VERSION ""

NS_ :

BS_:

BU_: IOT_Gateway BMC

BO_ 3221225472 VECTOR__INDEPENDENT_SIG_MSG: 0 Vector__XXX
 SG_ RUL_HP_1 : 0|16@1+ (1,0) [0|65535] "" Vector__XXX
 SG_ RUL_HP_0 : 0|16@1+ (1,0) [0|65535] "" Vector__XXX
 SG_ RUL_HE_1 : 0|16@1+ (1,0) [0|65535] "" Vector__XXX
 SG_ RUL_HE_0 : 0|16@1+ (1,0) [0|65535] "" Vector__XXX

BO_ 130 CellPwrHi_4: 64 BMC
 SG_ TAuxBattMonEgyHi_16_1 : 496|16@1+ (0.0078125,0) [0|511.9921875] "°K"  IOT_Gateway
 SG_ TAuxBattMonEgyHi_15_1 : 480|16@1+ (0.0078125,0) [0|511.9921875] "°K"  IOT_Gateway
 SG_ TAuxBattMonEgyHi_14_1 : 464|16@1+ (0.0078125,0) [0|511.9921875] "°K"  IOT_Gateway
 SG_ TAuxBattMonEgyHi_13_1 : 448|16@1+ (0.0078125,0) [0|511.9921875] "°K"  IOT_Gateway
 SG_ TAuxBattMonEgyHi_12_1 : 432|16@1+ (0.0078125,0) [0|511.9921875] "°K"  IOT_Gateway
 SG_ TAuxBattMonEgyHi_11_1 : 416|16@1+ (0.0078125,0) [0|511.9921875] "°K"  IOT_Gateway
 SG_ TAuxBattMonEgyHi_10_1 : 400|16@1+ (0.0078125,0) [0|511.9921875] "°K"  IOT_Gateway
 SG_ TAuxBattMonEgyHi_9_1 : 384|16@1+ (0.0078125,0) [0|511.9921875] "°K"  IOT_Gateway
 SG_ TAuxBattMonEgyHi_8_1 : 368|16@1+ (0.0078125,0) [0|511.9921875] "°K"  IOT_Gateway
 SG_ TAuxBattMonEgyHi_7_1 : 352|16@1+ (0.0078125,0) [0|511.9921875] "°K"  IOT_Gateway
 SG_ TAuxBattMonEgyHi_6_1 : 336|16@1+ (0.0078125,0) [0|511.9921875] "°K"  IOT_Gateway
 SG_ TAuxBattMonEgyHi_5_1 : 320|16@1+ (0.0078125,0) [0|511.9921875] "°K"  IOT_Gateway
 SG_ TAuxBattMonEgyHi_4_1 : 304|16@1+ (0.0078125,0) [0|511.9921875] "°K"  IOT_Gateway
 SG_ TAuxBattMonEgyHi_3_1 : 288|16@1+ (0.0078125,0) [0|511.9921875] "°K"  IOT_Gateway
 SG_ TAuxBattMonEgyHi_2_1 : 272|16@1+ (0.0078125,0) [0|511.9921875] "°K"  IOT_Gateway
 SG_ TAuxBattMonEgyHi_1_1 : 256|16@1+ (0.0078125,0) [0|511.9921875] "°K"  IOT_Gateway
 SG_ TAuxBattMonPwrHi_16_1 : 240|16@1+ (0.0078125,0) [0|511.9921875] "°K"  IOT_Gateway
 SG_ TAuxBattMonPwrHi_15_1 : 224|16@1+ (0.0078125,0) [0|511.9921875] "°K"  IOT_Gateway
 SG_ TAuxBattMonPwrHi_14_1 : 208|16@1+ (0.0078125,0) [0|511.9921875] "°K"  IOT_Gateway
 SG_ TAuxBattMonPwrHi_13_1 : 192|16@1+ (0.0078125,0) [0|511.9921875] "°K"  IOT_Gateway
 SG_ TAuxBattMonPwrHi_12_1 : 176|16@1+ (0.0078125,0) [0|511.9921875] "°K"  IOT_Gateway
 SG_ TAuxBattMonPwrHi_11_1 : 160|16@1+ (0.0078125,0) [0|511.9921875] "°K"  IOT_Gateway
 SG_ TAuxBattMonPwrHi_10_1 : 144|16@1+ (0.0078125,0) [0|511.9921875] "°K"  IOT_Gateway
 SG_ TAuxBattMonPwrHi_9_1 : 128|16@1+ (0.0078125,0) [0|511.9921875] "°K"  IOT_Gateway
 SG_ TAuxBattMonPwrHi_8_1 : 112|16@1+ (0.0078125,0) [0|511.9921875] "°K"  IOT_Gateway
 SG_ TAuxBattMonPwrHi_7_1 : 96|16@1+ (0.0078125,0) [0|511.9921875] "°K"  IOT_Gateway
 SG_ TAuxBattMonPwrHi_6_1 : 80|16@1+ (0.0078125,0) [0|511.9921875] "°K"  IOT_Gateway
 SG_ TAuxBattMonPwrHi_5_1 : 64|16@1+ (0.0078125,0) [0|511.9921875] "°K"  IOT_Gateway
 SG_ TAuxBattMonPwrHi_4_1 : 48|16@1+ (0.0078125,0) [0|511.9921875] "°K"  IOT_Gateway
 SG_ TAuxBattMonPwrHi_3_1 : 32|16@1+ (0.0078125,0) [0|511.9921875] "°K"  IOT_Gateway
 SG_ TAuxBattMonPwrHi_2_1 : 16|16@1+ (0.0078125,0) [0|511.9921875] "°K"  IOT_Gateway
 SG_ TAuxBattMonPwrHi_1_1 : 0|16@1+ (0.0078125,0) [0|511.9921875] "°K"  IOT_Gateway

BO_ 111 TCellBattEgyHi_16: 12 BMC
 SG_ TCellBattEgyHi_16_6 : 80|16@1+ (0.0078125,0) [0|511.9921875] "°K"  IOT_Gateway
 SG_ TCellBattEgyHi_16_5 : 64|16@1+ (0.0078125,0) [0|511.9921875] "°K"  IOT_Gateway
 SG_ TCellBattEgyHi_16_4 : 48|16@1+ (0.0078125,0) [0|511.9921875] "°K"  IOT_Gateway
 SG_ TCellBattEgyHi_16_3 : 32|16@1+ (0.0078125,0) [0|511.9921875] "°K"  IOT_Gateway
 SG_ TCellBattEgyHi_16_2 : 16|16@1+ (0.0078125,0) [0|511.9921875] "°K"  IOT_Gateway
 SG_ TCellBattEgyHi_16_1 : 0|16@1+ (0.0078125,0) [0|511.9921875] "°K"  IOT_Gateway

BO_ 110 TCellBattEgyHi_15: 12 BMC
 SG_ TCellBattEgyHi_15_6 : 80|16@1+ (0.0078125,0) [0|511.9921875] "°K"  IOT_Gateway
 SG_ TCellBattEgyHi_15_5 : 64|16@1+ (0.0078125,0) [0|511.9921875] "°K"  IOT_Gateway
 SG_ TCellBattEgyHi_15_4 : 48|16@1+ (0.0078125,0) [0|511.9921875] "°K"  IOT_Gateway
 SG_ TCellBattEgyHi_15_3 : 32|16@1+ (0.0078125,0) [0|511.9921875] "°K"  IOT_Gateway
 SG_ TCellBattEgyHi_15_2 : 16|16@1+ (0.0078125,0) [0|511.9921875] "°K"  IOT_Gateway
 SG_ TCellBattEgyHi_15_1 : 0|16@1+ (0.0078125,0) [0|511.9921875] "°K"  IOT_Gateway

BO_ 109 TCellBattEgyHi_14: 12 BMC
 SG_ TCellBattEgyHi_14_6 : 80|16@1+ (0.0078125,0) [0|511.9921875] "°K"  IOT_Gateway
 SG_ TCellBattEgyHi_14_5 : 64|16@1+ (0.0078125,0) [0|511.9921875] "°K"  IOT_Gateway
 SG_ TCellBattEgyHi_14_4 : 48|16@1+ (0.0078125,0) [0|511.9921875] "°K"  IOT_Gateway
 SG_ TCellBattEgyHi_14_3 : 32|16@1+ (0.0078125,0) [0|511.9921875] "°K"  IOT_Gateway
 SG_ TCellBattEgyHi_14_2 : 16|16@1+ (0.0078125,0) [0|511.9921875] "°K"  IOT_Gateway
 SG_ TCellBattEgyHi_14_1 : 0|16@1+ (0.0078125,0) [0|511.9921875] "°K"  IOT_Gateway

BO_ 108 TCellBattEgyHi_13: 12 BMC
 SG_ TCellBattEgyHi_13_6 : 80|16@1+ (0.0078125,0) [0|511.9921875] "°K"  IOT_Gateway
 SG_ TCellBattEgyHi_13_5 : 64|16@1+ (0.0078125,0) [0|511.9921875] "°K"  IOT_Gateway
 SG_ TCellBattEgyHi_13_4 : 48|16@1+ (0.0078125,0) [0|511.9921875] "°K"  IOT_Gateway
 SG_ TCellBattEgyHi_13_3 : 32|16@1+ (0.0078125,0) [0|511.9921875] "°K"  IOT_Gateway
 SG_ TCellBattEgyHi_13_2 : 16|16@1+ (0.0078125,0) [0|511.9921875] "°K"  IOT_Gateway
 SG_ TCellBattEgyHi_13_1 : 0|16@1+ (0.0078125,0) [0|511.9921875] "°K"  IOT_Gateway

BO_ 95 TCellBattPwrHi_16: 12 BMC
 SG_ TCellBattPwrHi_16_6 : 80|16@1+ (0.0078125,0) [0|511.9921875] "°K" Vector__XXX
 SG_ TCellBattPwrHi_16_5 : 64|16@1+ (0.0078125,0) [0|511.9921875] "°K" Vector__XXX
 SG_ TCellBattPwrHi_16_4 : 48|16@1+ (0.0078125,0) [0|511.9921875] "°K" Vector__XXX
 SG_ TCellBattPwrHi_16_3 : 32|16@1+ (0.0078125,0) [0|511.9921875] "°K" Vector__XXX
 SG_ TCellBattPwrHi_16_2 : 16|16@1+ (0.0078125,0) [0|511.9921875] "°K" Vector__XXX
 SG_ TCellBattPwrHi_16_1 : 0|16@1+ (0.0078125,0) [0|511.9921875] "°K" Vector__XXX

BO_ 94 TCellBattPwrHi_15: 12 BMC
 SG_ TCellBattPwrHi_15_6 : 80|16@1+ (0.0078125,0) [0|511.9921875] "°K" Vector__XXX
 SG_ TCellBattPwrHi_15_5 : 64|16@1+ (0.0078125,0) [0|511.9921875] "°K" Vector__XXX
 SG_ TCellBattPwrHi_15_4 : 48|16@1+ (0.0078125,0) [0|511.9921875] "°K" Vector__XXX
 SG_ TCellBattPwrHi_15_3 : 32|16@1+ (0.0078125,0) [0|511.9921875] "°K" Vector__XXX
 SG_ TCellBattPwrHi_15_2 : 16|16@1+ (0.0078125,0) [0|511.9921875] "°K" Vector__XXX
 SG_ TCellBattPwrHi_15_1 : 0|16@1+ (0.0078125,0) [0|511.9921875] "°K" Vector__XXX

BO_ 93 TCellBattPwrHi_14: 12 BMC
 SG_ TCellBattPwrHi_14_6 : 80|16@1+ (0.0078125,0) [0|511.9921875] "°K" Vector__XXX
 SG_ TCellBattPwrHi_14_5 : 64|16@1+ (0.0078125,0) [0|511.9921875] "°K" Vector__XXX
 SG_ TCellBattPwrHi_14_4 : 48|16@1+ (0.0078125,0) [0|511.9921875] "°K" Vector__XXX
 SG_ TCellBattPwrHi_14_3 : 32|16@1+ (0.0078125,0) [0|511.9921875] "°K" Vector__XXX
 SG_ TCellBattPwrHi_14_2 : 16|16@1+ (0.0078125,0) [0|511.9921875] "°K" Vector__XXX
 SG_ TCellBattPwrHi_14_1 : 0|16@1+ (0.0078125,0) [0|511.9921875] "°K" Vector__XXX

BO_ 92 TCellBattPwrHi_13: 12 BMC
 SG_ TCellBattPwrHi_13_6 : 80|16@1+ (0.0078125,0) [0|511.9921875] "°K" Vector__XXX
 SG_ TCellBattPwrHi_13_5 : 64|16@1+ (0.0078125,0) [0|511.9921875] "°K" Vector__XXX
 SG_ TCellBattPwrHi_13_4 : 48|16@1+ (0.0078125,0) [0|511.9921875] "°K" Vector__XXX
 SG_ TCellBattPwrHi_13_3 : 32|16@1+ (0.0078125,0) [0|511.9921875] "°K" Vector__XXX
 SG_ TCellBattPwrHi_13_2 : 16|16@1+ (0.0078125,0) [0|511.9921875] "°K" Vector__XXX
 SG_ TCellBattPwrHi_13_1 : 0|16@1+ (0.0078125,0) [0|511.9921875] "°K" Vector__XXX

BO_ 1654 Sensor_Msg8_8: 8 BMC
 SG_ VERSION_MINOR_8 : 8|8@1+ (1,0) [0|255] ""  IOT_Gateway
 SG_ VERSION_MAJOR_8 : 0|8@1+ (1,0) [0|255] ""  IOT_Gateway

BO_ 1638 Sensor_Msg8_7: 8 BMC
 SG_ VERSION_MINOR_7 : 8|8@1+ (1,0) [0|255] ""  IOT_Gateway
 SG_ VERSION_MAJOR_7 : 0|8@1+ (1,0) [0|255] ""  IOT_Gateway

BO_ 1606 Sensor_Msg8_5: 8 BMC
 SG_ VERSION_MINOR_5 : 8|8@1+ (1,0) [0|255] ""  IOT_Gateway
 SG_ VERSION_MAJOR_5 : 0|8@1+ (1,0) [0|255] ""  IOT_Gateway

BO_ 1590 Sensor_Msg8_4: 8 BMC
 SG_ VERSION_MINOR_4 : 8|8@1+ (1,0) [0|255] ""  IOT_Gateway
 SG_ VERSION_MAJOR_4 : 0|8@1+ (1,0) [0|255] ""  IOT_Gateway

BO_ 1622 Sensor_Msg8_6: 8 BMC
 SG_ VERSION_MINOR_6 : 8|8@1+ (1,0) [0|255] ""  IOT_Gateway
 SG_ VERSION_MAJOR_6 : 0|8@1+ (1,0) [0|255] ""  IOT_Gateway

BO_ 1574 Sensor_Msg8_3: 8 BMC
 SG_ VERSION_MINOR_3 : 8|8@1+ (1,0) [0|255] ""  IOT_Gateway
 SG_ VERSION_MAJOR_3 : 0|8@1+ (1,0) [0|255] ""  IOT_Gateway

BO_ 1558 Sensor_Msg8_2: 8 BMC
 SG_ VERSION_MINOR_2 : 8|8@1+ (1,0) [0|255] ""  IOT_Gateway
 SG_ VERSION_MAJOR_2 : 0|8@1+ (1,0) [0|255] ""  IOT_Gateway

BO_ 1542 Sensor_Msg8_1: 8 BMC
 SG_ VERSION_MINOR_1 : 8|8@1+ (1,0) [0|255] ""  IOT_Gateway
 SG_ VERSION_MAJOR_1 : 0|8@1+ (1,0) [0|255] ""  IOT_Gateway

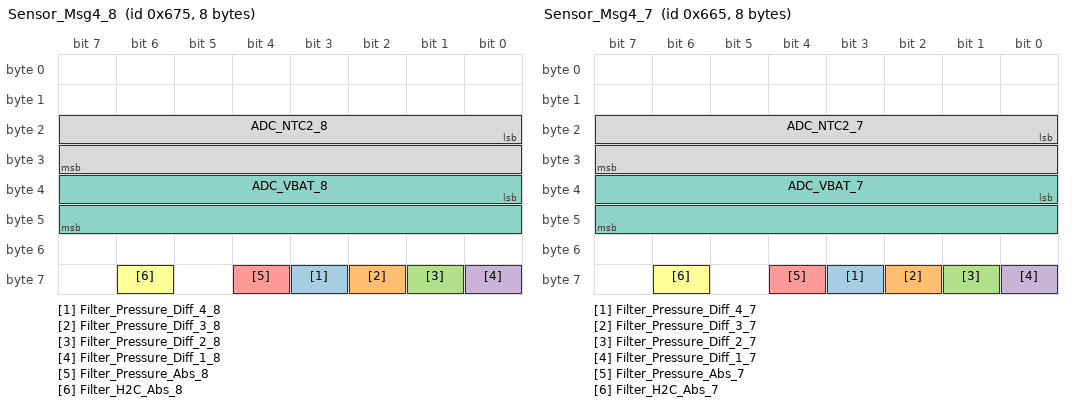
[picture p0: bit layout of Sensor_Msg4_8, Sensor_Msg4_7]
BO_ 1653 Sensor_Msg4_8: 8 BMC
 SG_ Filter_Pressure_Diff_4_8 : 59|1@1+ (1,0) [0|1] ""  IOT_Gateway
 SG_ Filter_Pressure_Diff_3_8 : 58|1@1+ (1,0) [0|1] ""  IOT_Gateway
 SG_ Filter_Pressure_Diff_2_8 : 57|1@1+ (1,0) [0|1] ""  IOT_Gateway
 SG_ Filter_Pressure_Diff_1_8 : 56|1@1+ (1,0) [0|1] ""  IOT_Gateway
 SG_ Filter_Pressure_Abs_8 : 60|1@1+ (1,0) [0|1] ""  IOT_Gateway
 SG_ Filter_H2C_Abs_8 : 62|1@1+ (1,0) [0|1] ""  IOT_Gateway
 SG_ ADC_VBAT_8 : 32|16@1- (0.01,0) [0|100] "V"  IOT_Gateway
 SG_ ADC_NTC2_8 : 16|16@1- (0.01,0) [-40|125] "°C"  IOT_Gateway

BO_ 1637 Sensor_Msg4_7: 8 BMC
 SG_ Filter_Pressure_Diff_4_7 : 59|1@1+ (1,0) [0|1] ""  IOT_Gateway
 SG_ Filter_Pressure_Diff_3_7 : 58|1@1+ (1,0) [0|1] ""  IOT_Gateway
 SG_ Filter_Pressure_Diff_2_7 : 57|1@1+ (1,0) [0|1] ""  IOT_Gateway
 SG_ Filter_Pressure_Diff_1_7 : 56|1@1+ (1,0) [0|1] ""  IOT_Gateway
 SG_ Filter_Pressure_Abs_7 : 60|1@1+ (1,0) [0|1] ""  IOT_Gateway
 SG_ Filter_H2C_Abs_7 : 62|1@1+ (1,0) [0|1] ""  IOT_Gateway
 SG_ ADC_VBAT_7 : 32|16@1- (0.01,0) [0|100] "V"  IOT_Gateway
 SG_ ADC_NTC2_7 : 16|16@1- (0.01,0) [-40|125] "°C"  IOT_Gateway

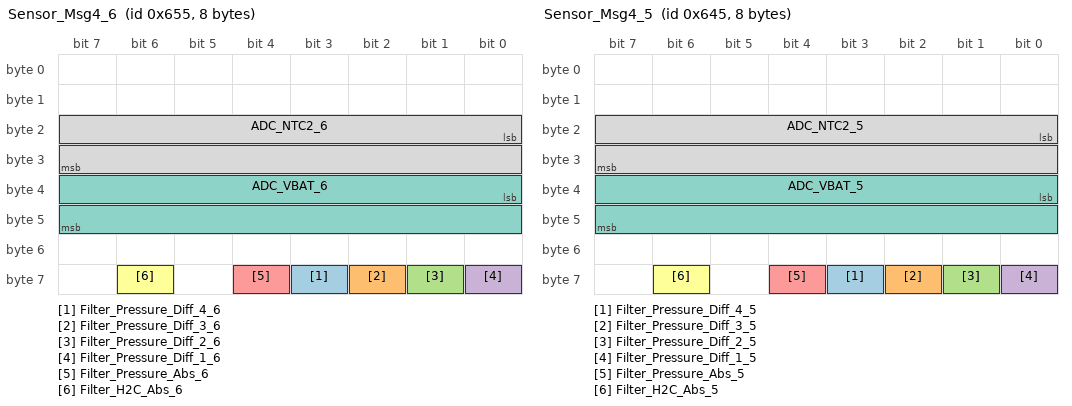
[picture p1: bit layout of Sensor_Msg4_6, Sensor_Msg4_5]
BO_ 1621 Sensor_Msg4_6: 8 BMC
 SG_ Filter_Pressure_Diff_4_6 : 59|1@1+ (1,0) [0|1] ""  IOT_Gateway
 SG_ Filter_Pressure_Diff_3_6 : 58|1@1+ (1,0) [0|1] ""  IOT_Gateway
 SG_ Filter_Pressure_Diff_2_6 : 57|1@1+ (1,0) [0|1] ""  IOT_Gateway
 SG_ Filter_Pressure_Diff_1_6 : 56|1@1+ (1,0) [0|1] ""  IOT_Gateway
 SG_ Filter_Pressure_Abs_6 : 60|1@1+ (1,0) [0|1] ""  IOT_Gateway
 SG_ Filter_H2C_Abs_6 : 62|1@1+ (1,0) [0|1] ""  IOT_Gateway
 SG_ ADC_VBAT_6 : 32|16@1- (0.01,0) [0|100] "V"  IOT_Gateway
 SG_ ADC_NTC2_6 : 16|16@1- (0.01,0) [-40|125] "°C"  IOT_Gateway

BO_ 1605 Sensor_Msg4_5: 8 BMC
 SG_ Filter_Pressure_Diff_4_5 : 59|1@1+ (1,0) [0|1] ""  IOT_Gateway
 SG_ Filter_Pressure_Diff_3_5 : 58|1@1+ (1,0) [0|1] ""  IOT_Gateway
 SG_ Filter_Pressure_Diff_2_5 : 57|1@1+ (1,0) [0|1] ""  IOT_Gateway
 SG_ Filter_Pressure_Diff_1_5 : 56|1@1+ (1,0) [0|1] ""  IOT_Gateway
 SG_ Filter_Pressure_Abs_5 : 60|1@1+ (1,0) [0|1] ""  IOT_Gateway
 SG_ Filter_H2C_Abs_5 : 62|1@1+ (1,0) [0|1] ""  IOT_Gateway
 SG_ ADC_VBAT_5 : 32|16@1- (0.01,0) [0|100] "V"  IOT_Gateway
 SG_ ADC_NTC2_5 : 16|16@1- (0.01,0) [-40|125] "°C"  IOT_Gateway

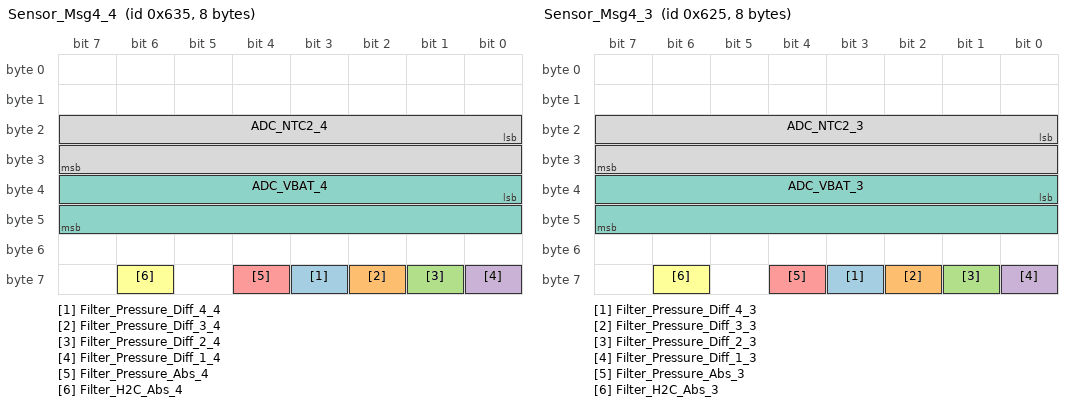
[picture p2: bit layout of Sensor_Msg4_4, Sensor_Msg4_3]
BO_ 1589 Sensor_Msg4_4: 8 BMC
 SG_ Filter_Pressure_Diff_4_4 : 59|1@1+ (1,0) [0|1] ""  IOT_Gateway
 SG_ Filter_Pressure_Diff_3_4 : 58|1@1+ (1,0) [0|1] ""  IOT_Gateway
 SG_ Filter_Pressure_Diff_2_4 : 57|1@1+ (1,0) [0|1] ""  IOT_Gateway
 SG_ Filter_Pressure_Diff_1_4 : 56|1@1+ (1,0) [0|1] ""  IOT_Gateway
 SG_ Filter_Pressure_Abs_4 : 60|1@1+ (1,0) [0|1] ""  IOT_Gateway
 SG_ Filter_H2C_Abs_4 : 62|1@1+ (1,0) [0|1] ""  IOT_Gateway
 SG_ ADC_VBAT_4 : 32|16@1- (0.01,0) [0|100] "V"  IOT_Gateway
 SG_ ADC_NTC2_4 : 16|16@1- (0.01,0) [-40|125] "°C"  IOT_Gateway

BO_ 1573 Sensor_Msg4_3: 8 BMC
 SG_ Filter_Pressure_Diff_4_3 : 59|1@1+ (1,0) [0|1] ""  IOT_Gateway
 SG_ Filter_Pressure_Diff_3_3 : 58|1@1+ (1,0) [0|1] ""  IOT_Gateway
 SG_ Filter_Pressure_Diff_2_3 : 57|1@1+ (1,0) [0|1] ""  IOT_Gateway
 SG_ Filter_Pressure_Diff_1_3 : 56|1@1+ (1,0) [0|1] ""  IOT_Gateway
 SG_ Filter_Pressure_Abs_3 : 60|1@1+ (1,0) [0|1] ""  IOT_Gateway
 SG_ Filter_H2C_Abs_3 : 62|1@1+ (1,0) [0|1] ""  IOT_Gateway
 SG_ ADC_VBAT_3 : 32|16@1- (0.01,0) [0|100] "V"  IOT_Gateway
 SG_ ADC_NTC2_3 : 16|16@1- (0.01,0) [-40|125] "°C"  IOT_Gateway

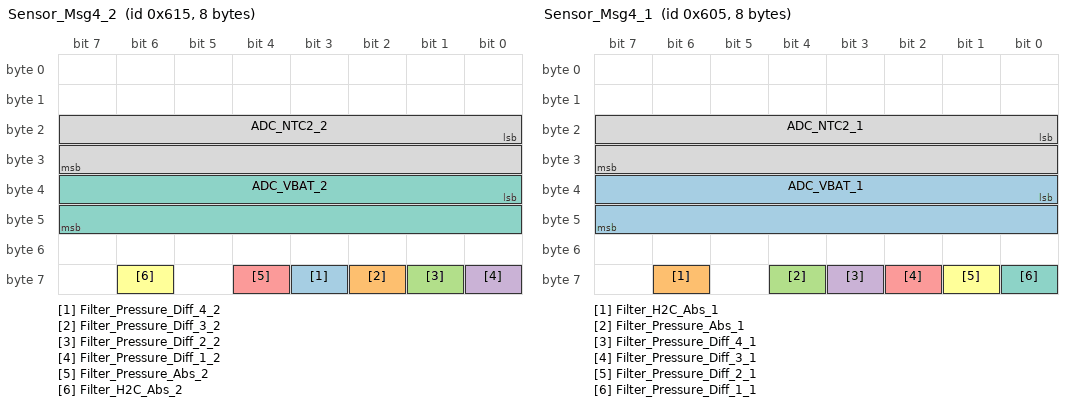
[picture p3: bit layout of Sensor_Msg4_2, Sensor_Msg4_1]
BO_ 1557 Sensor_Msg4_2: 8 BMC
 SG_ Filter_Pressure_Diff_4_2 : 59|1@1+ (1,0) [0|1] ""  IOT_Gateway
 SG_ Filter_Pressure_Diff_3_2 : 58|1@1+ (1,0) [0|1] ""  IOT_Gateway
 SG_ Filter_Pressure_Diff_2_2 : 57|1@1+ (1,0) [0|1] ""  IOT_Gateway
 SG_ Filter_Pressure_Diff_1_2 : 56|1@1+ (1,0) [0|1] ""  IOT_Gateway
 SG_ Filter_Pressure_Abs_2 : 60|1@1+ (1,0) [0|1] ""  IOT_Gateway
 SG_ Filter_H2C_Abs_2 : 62|1@1+ (1,0) [0|1] ""  IOT_Gateway
 SG_ ADC_VBAT_2 : 32|16@1- (0.01,0) [0|100] "V"  IOT_Gateway
 SG_ ADC_NTC2_2 : 16|16@1- (0.01,0) [-40|125] "°C"  IOT_Gateway

BO_ 1541 Sensor_Msg4_1: 8 BMC
 SG_ ADC_VBAT_1 : 32|16@1- (0.01,0) [0|100] "V"  IOT_Gateway
 SG_ Filter_H2C_Abs_1 : 62|1@1+ (1,0) [0|1] ""  IOT_Gateway
 SG_ Filter_Pressure_Abs_1 : 60|1@1+ (1,0) [0|1] ""  IOT_Gateway
 SG_ Filter_Pressure_Diff_4_1 : 59|1@1+ (1,0) [0|1] ""  IOT_Gateway
 SG_ Filter_Pressure_Diff_3_1 : 58|1@1+ (1,0) [0|1] ""  IOT_Gateway
 SG_ Filter_Pressure_Diff_2_1 : 57|1@1+ (1,0) [0|1] ""  IOT_Gateway
 SG_ Filter_Pressure_Diff_1_1 : 56|1@1+ (1,0) [0|1] ""  IOT_Gateway
 SG_ ADC_NTC2_1 : 16|16@1- (0.01,0) [-40|125] "°C"  IOT_Gateway

BO_ 1652 Sensor_Msg3_8: 8 BMC
 SG_ KP466_Status_8 : 16|8@1+ (1,0) [0|255] ""  IOT_Gateway
 SG_ KP466_Pressure_8 : 32|32@1- (0.001,0) [60|165] "kPa"  IOT_Gateway

BO_ 1636 Sensor_Msg3_7: 8 BMC
 SG_ KP466_Status_7 : 16|8@1+ (1,0) [0|255] ""  IOT_Gateway
 SG_ KP466_Pressure_7 : 32|32@1- (0.001,0) [60|165] "kPa"  IOT_Gateway

BO_ 1620 Sensor_Msg3_6: 8 BMC
 SG_ KP466_Status_6 : 16|8@1+ (1,0) [0|255] ""  IOT_Gateway
 SG_ KP466_Pressure_6 : 32|32@1- (0.001,0) [60|165] "kPa"  IOT_Gateway

BO_ 1604 Sensor_Msg3_5: 8 BMC
 SG_ KP466_Status_5 : 16|8@1+ (1,0) [0|255] ""  IOT_Gateway
 SG_ KP466_Pressure_5 : 32|32@1- (0.001,0) [60|165] "kPa"  IOT_Gateway

BO_ 1588 Sensor_Msg3_4: 8 BMC
 SG_ KP466_Status_4 : 16|8@1+ (1,0) [0|255] ""  IOT_Gateway
 SG_ KP466_Pressure_4 : 32|32@1- (0.001,0) [60|165] "kPa"  IOT_Gateway

BO_ 1572 Sensor_Msg3_3: 8 BMC
 SG_ KP466_Status_3 : 16|8@1+ (1,0) [0|255] ""  IOT_Gateway
 SG_ KP466_Pressure_3 : 32|32@1- (0.001,0) [60|165] "kPa"  IOT_Gateway

BO_ 1556 Sensor_Msg3_2: 8 BMC
 SG_ KP466_Status_2 : 16|8@1+ (1,0) [0|255] ""  IOT_Gateway
 SG_ KP466_Pressure_2 : 32|32@1- (0.001,0) [60|165] "kPa"  IOT_Gateway

BO_ 1540 Sensor_Msg3_1: 8 BMC
 SG_ KP466_Pressure_1 : 32|32@1- (0.001,0) [60|165] "kPa"  IOT_Gateway
 SG_ KP466_Status_1 : 16|8@1+ (1,0) [0|255] ""  IOT_Gateway

BO_ 1650 Sensor_Msg1_8: 8 BMC
 SG_ SHT_Status_8 : 56|8@1+ (1,0) [0|255] ""  IOT_Gateway
 SG_ SHT_Humidity_8 : 0|32@1- (0.001,0) [0|100] "%"  IOT_Gateway

BO_ 1634 Sensor_Msg1_7: 8 BMC
 SG_ SHT_Status_7 : 56|8@1+ (1,0) [0|255] ""  IOT_Gateway
 SG_ SHT_Humidity_7 : 0|32@1- (0.001,0) [0|100] "%"  IOT_Gateway

BO_ 1618 Sensor_Msg1_6: 8 BMC
 SG_ SHT_Status_6 : 56|8@1+ (1,0) [0|255] ""  IOT_Gateway
 SG_ SHT_Humidity_6 : 0|32@1- (0.001,0) [0|100] "%"  IOT_Gateway

BO_ 1602 Sensor_Msg1_5: 8 BMC
 SG_ SHT_Status_5 : 56|8@1+ (1,0) [0|255] ""  IOT_Gateway
 SG_ SHT_Humidity_5 : 0|32@1- (0.001,0) [0|100] "%"  IOT_Gateway

BO_ 1586 Sensor_Msg1_4: 8 BMC
 SG_ SHT_Status_4 : 56|8@1+ (1,0) [0|255] ""  IOT_Gateway
 SG_ SHT_Humidity_4 : 0|32@1- (0.001,0) [0|100] "%"  IOT_Gateway

BO_ 1570 Sensor_Msg1_3: 8 BMC
 SG_ SHT_Status_3 : 56|8@1+ (1,0) [0|255] ""  IOT_Gateway
 SG_ SHT_Humidity_3 : 0|32@1- (0.001,0) [0|100] "%"  IOT_Gateway

BO_ 1554 Sensor_Msg1_2: 8 BMC
 SG_ SHT_Status_2 : 56|8@1+ (1,0) [0|255] ""  IOT_Gateway
 SG_ SHT_Humidity_2 : 0|32@1- (0.001,0) [0|100] "%"  IOT_Gateway

BO_ 1538 Sensor_Msg1_1: 8 BMC
 SG_ SHT_Status_1 : 56|8@1+ (1,0) [0|255] ""  IOT_Gateway
 SG_ SHT_Humidity_1 : 0|32@1- (0.001,0) [0|100] "%"  IOT_Gateway

BO_ 1649 Sensor_Msg0_8: 8 BMC
 SG_ SHT_Temperature_8 : 32|32@1- (0.001,0) [-40|105] "°C"  IOT_Gateway

BO_ 1633 Sensor_Msg0_7: 8 BMC
 SG_ SHT_Temperature_7 : 32|32@1- (0.001,0) [-40|105] "°C"  IOT_Gateway

BO_ 1617 Sensor_Msg0_6: 8 BMC
 SG_ SHT_Temperature_6 : 32|32@1- (0.001,0) [-40|105] "°C"  IOT_Gateway

BO_ 1601 Sensor_Msg0_5: 8 BMC
 SG_ SHT_Temperature_5 : 32|32@1- (0.001,0) [-40|105] "°C"  IOT_Gateway

BO_ 1585 Sensor_Msg0_4: 8 BMC
 SG_ SHT_Temperature_4 : 32|32@1- (0.001,0) [-40|105] "°C"  IOT_Gateway

BO_ 1569 Sensor_Msg0_3: 8 BMC
 SG_ SHT_Temperature_3 : 32|32@1- (0.001,0) [-40|105] "°C"  IOT_Gateway

BO_ 1553 Sensor_Msg0_2: 8 BMC
 SG_ SHT_Temperature_2 : 32|32@1- (0.001,0) [-40|105] "°C"  IOT_Gateway

BO_ 1537 Sensor_Msg0_1: 8 BMC
 SG_ SHT_Temperature_1 : 32|32@1- (0.001,0) [-40|105] "°C"  IOT_Gateway

BO_ 1648 H2CS_DF_8: 8 BMC
 SG_ H2CS_H2C_8 : 16|12@1+ (0.01,-2) [-2|38.95] "%"  IOT_Gateway

BO_ 1632 H2CS_DF_7: 8 BMC
 SG_ H2CS_H2C_7 : 16|12@1+ (0.01,-2) [-2|38.95] "%"  IOT_Gateway

BO_ 1616 H2CS_DF_6: 8 BMC
 SG_ H2CS_H2C_6 : 16|12@1+ (0.01,-2) [-2|38.95] "%"  IOT_Gateway

BO_ 1600 H2CS_DF_5: 8 BMC
 SG_ H2CS_H2C_5 : 16|12@1+ (0.01,-2) [-2|38.95] "%"  IOT_Gateway

BO_ 1584 H2CS_DF_4: 8 BMC
 SG_ H2CS_H2C_4 : 16|12@1+ (0.01,-2) [-2|38.95] "%"  IOT_Gateway

BO_ 1568 H2CS_DF_3: 8 BMC
 SG_ H2CS_H2C_3 : 16|12@1+ (0.01,-2) [-2|38.95] "%"  IOT_Gateway

BO_ 1552 H2CS_DF_2: 8 BMC
 SG_ H2CS_H2C_2 : 16|12@1+ (0.01,-2) [-2|38.95] "%"  IOT_Gateway

BO_ 1536 H2CS_DF_1: 8 BMC
 SG_ H2CS_H2C_1 : 16|12@1+ (0.01,-2) [-2|38.95] "%"  IOT_Gateway

BO_ 127 RatChaCellBattEgyHi_8: 64 BMC
 SG_ RatChaCellBattEgyHi_16_16 : 496|16@1+ (0.006103515625,-2) [-2|1.9999] ""  IOT_Gateway
 SG_ RatChaCellBattEgyHi_16_15 : 480|16@1+ (0.006103515625,-2) [-2|1.9999] ""  IOT_Gateway
 SG_ RatChaCellBattEgyHi_16_14 : 464|16@1+ (0.006103515625,-2) [-2|1.9999] ""  IOT_Gateway
 SG_ RatChaCellBattEgyHi_16_13 : 448|16@1+ (0.006103515625,-2) [-2|1.9999] ""  IOT_Gateway
 SG_ RatChaCellBattEgyHi_16_12 : 432|16@1+ (0.006103515625,-2) [-2|1.9999] ""  IOT_Gateway
 SG_ RatChaCellBattEgyHi_16_11 : 416|16@1+ (0.006103515625,-2) [-2|1.9999] ""  IOT_Gateway
 SG_ RatChaCellBattEgyHi_16_10 : 400|16@1+ (0.006103515625,-2) [-2|1.9999] ""  IOT_Gateway
 SG_ RatChaCellBattEgyHi_16_9 : 384|16@1+ (0.006103515625,-2) [-2|1.9999] ""  IOT_Gateway
 SG_ RatChaCellBattEgyHi_16_8 : 368|16@1+ (0.006103515625,-2) [-2|1.9999] ""  IOT_Gateway
 SG_ RatChaCellBattEgyHi_16_7 : 352|16@1+ (0.006103515625,-2) [-2|1.9999] ""  IOT_Gateway
 SG_ RatChaCellBattEgyHi_16_6 : 336|16@1+ (0.006103515625,-2) [-2|1.9999] ""  IOT_Gateway
 SG_ RatChaCellBattEgyHi_16_5 : 320|16@1+ (0.006103515625,-2) [-2|1.9999] ""  IOT_Gateway
 SG_ RatChaCellBattEgyHi_16_4 : 304|16@1+ (0.006103515625,-2) [-2|1.9999] ""  IOT_Gateway
 SG_ RatChaCellBattEgyHi_16_3 : 288|16@1+ (0.006103515625,-2) [-2|1.9999] ""  IOT_Gateway
 SG_ RatChaCellBattEgyHi_16_2 : 272|16@1+ (0.006103515625,-2) [-2|1.9999] ""  IOT_Gateway
 SG_ RatChaCellBattEgyHi_16_1 : 256|16@1+ (0.006103515625,-2) [-2|1.9999] ""  IOT_Gateway
 SG_ RatChaCellBattEgyHi_15_16 : 240|16@1+ (0.006103515625,-2) [-2|1.9999] ""  IOT_Gateway
 SG_ RatChaCellBattEgyHi_15_15 : 224|16@1+ (0.006103515625,-2) [-2|1.9999] ""  IOT_Gateway
 SG_ RatChaCellBattEgyHi_15_14 : 208|16@1+ (0.006103515625,-2) [-2|1.9999] ""  IOT_Gateway
 SG_ RatChaCellBattEgyHi_15_13 : 192|16@1+ (0.006103515625,-2) [-2|1.9999] ""  IOT_Gateway
 SG_ RatChaCellBattEgyHi_15_12 : 176|16@1+ (0.006103515625,-2) [-2|1.9999] ""  IOT_Gateway
 SG_ RatChaCellBattEgyHi_15_11 : 160|16@1+ (0.006103515625,-2) [-2|1.9999] ""  IOT_Gateway
 SG_ RatChaCellBattEgyHi_15_10 : 144|16@1+ (0.006103515625,-2) [-2|1.9999] ""  IOT_Gateway
 SG_ RatChaCellBattEgyHi_15_9 : 128|16@1+ (0.006103515625,-2) [-2|1.9999] ""  IOT_Gateway
 SG_ RatChaCellBattEgyHi_15_8 : 112|16@1+ (0.006103515625,-2) [-2|1.9999] ""  IOT_Gateway
 SG_ RatChaCellBattEgyHi_15_7 : 96|16@1+ (0.006103515625,-2) [-2|1.9999] ""  IOT_Gateway
 SG_ RatChaCellBattEgyHi_15_6 : 80|16@1+ (0.006103515625,-2) [-2|1.9999] ""  IOT_Gateway
 SG_ RatChaCellBattEgyHi_15_5 : 64|16@1+ (0.006103515625,-2) [-2|1.9999] ""  IOT_Gateway
 SG_ RatChaCellBattEgyHi_15_4 : 48|16@1+ (0.006103515625,-2) [-2|1.9999] ""  IOT_Gateway
 SG_ RatChaCellBattEgyHi_15_3 : 32|16@1+ (0.006103515625,-2) [-2|1.9999] ""  IOT_Gateway
 SG_ RatChaCellBattEgyHi_15_2 : 16|16@1+ (0.006103515625,-2) [-2|1.9999] ""  IOT_Gateway
 SG_ RatChaCellBattEgyHi_15_1 : 0|16@1+ (0.006103515625,-2) [-2|1.9999] ""  IOT_Gateway

BO_ 126 RatChaCellBattEgyHi_7: 64 BMC
 SG_ RatChaCellBattEgyHi_14_16 : 496|16@1+ (0.006103515625,-2) [-2|1.9999] ""  IOT_Gateway
 SG_ RatChaCellBattEgyHi_14_15 : 480|16@1+ (0.006103515625,-2) [-2|1.9999] ""  IOT_Gateway
 SG_ RatChaCellBattEgyHi_14_14 : 464|16@1+ (0.006103515625,-2) [-2|1.9999] ""  IOT_Gateway
 SG_ RatChaCellBattEgyHi_14_13 : 448|16@1+ (0.006103515625,-2) [-2|1.9999] ""  IOT_Gateway
 SG_ RatChaCellBattEgyHi_14_12 : 432|16@1+ (0.006103515625,-2) [-2|1.9999] ""  IOT_Gateway
 SG_ RatChaCellBattEgyHi_14_11 : 416|16@1+ (0.006103515625,-2) [-2|1.9999] ""  IOT_Gateway
 SG_ RatChaCellBattEgyHi_14_10 : 400|16@1+ (0.006103515625,-2) [-2|1.9999] ""  IOT_Gateway
 SG_ RatChaCellBattEgyHi_14_9 : 384|16@1+ (0.006103515625,-2) [-2|1.9999] ""  IOT_Gateway
 SG_ RatChaCellBattEgyHi_14_8 : 368|16@1+ (0.006103515625,-2) [-2|1.9999] ""  IOT_Gateway
 SG_ RatChaCellBattEgyHi_14_7 : 352|16@1+ (0.006103515625,-2) [-2|1.9999] ""  IOT_Gateway
 SG_ RatChaCellBattEgyHi_14_6 : 336|16@1+ (0.006103515625,-2) [-2|1.9999] ""  IOT_Gateway
 SG_ RatChaCellBattEgyHi_14_5 : 320|16@1+ (0.006103515625,-2) [-2|1.9999] ""  IOT_Gateway
 SG_ RatChaCellBattEgyHi_14_4 : 304|16@1+ (0.006103515625,-2) [-2|1.9999] ""  IOT_Gateway
 SG_ RatChaCellBattEgyHi_14_3 : 288|16@1+ (0.006103515625,-2) [-2|1.9999] ""  IOT_Gateway
 SG_ RatChaCellBattEgyHi_14_2 : 272|16@1+ (0.006103515625,-2) [-2|1.9999] ""  IOT_Gateway
 SG_ RatChaCellBattEgyHi_14_1 : 256|16@1+ (0.006103515625,-2) [-2|1.9999] ""  IOT_Gateway
 SG_ RatChaCellBattEgyHi_13_16 : 240|16@1+ (0.006103515625,-2) [-2|1.9999] ""  IOT_Gateway
 SG_ RatChaCellBattEgyHi_13_15 : 224|16@1+ (0.006103515625,-2) [-2|1.9999] ""  IOT_Gateway
 SG_ RatChaCellBattEgyHi_13_14 : 208|16@1+ (0.006103515625,-2) [-2|1.9999] ""  IOT_Gateway
 SG_ RatChaCellBattEgyHi_13_13 : 192|16@1+ (0.006103515625,-2) [-2|1.9999] ""  IOT_Gateway
 SG_ RatChaCellBattEgyHi_13_12 : 176|16@1+ (0.006103515625,-2) [-2|1.9999] ""  IOT_Gateway
 SG_ RatChaCellBattEgyHi_13_11 : 160|16@1+ (0.006103515625,-2) [-2|1.9999] ""  IOT_Gateway
 SG_ RatChaCellBattEgyHi_13_10 : 144|16@1+ (0.006103515625,-2) [-2|1.9999] ""  IOT_Gateway
 SG_ RatChaCellBattEgyHi_13_9 : 128|16@1+ (0.006103515625,-2) [-2|1.9999] ""  IOT_Gateway
 SG_ RatChaCellBattEgyHi_13_8 : 112|16@1+ (0.006103515625,-2) [-2|1.9999] ""  IOT_Gateway
 SG_ RatChaCellBattEgyHi_13_7 : 96|16@1+ (0.006103515625,-2) [-2|1.9999] ""  IOT_Gateway
 SG_ RatChaCellBattEgyHi_13_6 : 80|16@1+ (0.006103515625,-2) [-2|1.9999] ""  IOT_Gateway
 SG_ RatChaCellBattEgyHi_13_5 : 64|16@1+ (0.006103515625,-2) [-2|1.9999] ""  IOT_Gateway
 SG_ RatChaCellBattEgyHi_13_4 : 48|16@1+ (0.006103515625,-2) [-2|1.9999] ""  IOT_Gateway
 SG_ RatChaCellBattEgyHi_13_3 : 32|16@1+ (0.006103515625,-2) [-2|1.9999] ""  IOT_Gateway
 SG_ RatChaCellBattEgyHi_13_2 : 16|16@1+ (0.006103515625,-2) [-2|1.9999] ""  IOT_Gateway
 SG_ RatChaCellBattEgyHi_13_1 : 0|16@1+ (0.006103515625,-2) [-2|1.9999] ""  IOT_Gateway

BO_ 125 RatChaCellBattEgyHi_6: 64 BMC
 SG_ RatChaCellBattEgyHi_12_16 : 496|16@1+ (0.006103515625,-2) [-2|1.9999] ""  IOT_Gateway
 SG_ RatChaCellBattEgyHi_12_15 : 480|16@1+ (0.006103515625,-2) [-2|1.9999] ""  IOT_Gateway
 SG_ RatChaCellBattEgyHi_12_14 : 464|16@1+ (0.006103515625,-2) [-2|1.9999] ""  IOT_Gateway
 SG_ RatChaCellBattEgyHi_12_13 : 448|16@1+ (0.006103515625,-2) [-2|1.9999] ""  IOT_Gateway
 SG_ RatChaCellBattEgyHi_12_12 : 432|16@1+ (0.006103515625,-2) [-2|1.9999] ""  IOT_Gateway
 SG_ RatChaCellBattEgyHi_12_11 : 416|16@1+ (0.006103515625,-2) [-2|1.9999] ""  IOT_Gateway
 SG_ RatChaCellBattEgyHi_12_10 : 400|16@1+ (0.006103515625,-2) [-2|1.9999] ""  IOT_Gateway
 SG_ RatChaCellBattEgyHi_12_9 : 384|16@1+ (0.006103515625,-2) [-2|1.9999] ""  IOT_Gateway
 SG_ RatChaCellBattEgyHi_12_8 : 368|16@1+ (0.006103515625,-2) [-2|1.9999] ""  IOT_Gateway
 SG_ RatChaCellBattEgyHi_12_7 : 352|16@1+ (0.006103515625,-2) [-2|1.9999] ""  IOT_Gateway
 SG_ RatChaCellBattEgyHi_12_6 : 336|16@1+ (0.006103515625,-2) [-2|1.9999] ""  IOT_Gateway
 SG_ RatChaCellBattEgyHi_12_5 : 320|16@1+ (0.006103515625,-2) [-2|1.9999] ""  IOT_Gateway
 SG_ RatChaCellBattEgyHi_12_4 : 304|16@1+ (0.006103515625,-2) [-2|1.9999] ""  IOT_Gateway
 SG_ RatChaCellBattEgyHi_12_3 : 288|16@1+ (0.006103515625,-2) [-2|1.9999] ""  IOT_Gateway
 SG_ RatChaCellBattEgyHi_12_2 : 272|16@1+ (0.006103515625,-2) [-2|1.9999] ""  IOT_Gateway
 SG_ RatChaCellBattEgyHi_12_1 : 256|16@1+ (0.006103515625,-2) [-2|1.9999] ""  IOT_Gateway
 SG_ RatChaCellBattEgyHi_11_16 : 240|16@1+ (0.006103515625,-2) [-2|1.9999] ""  IOT_Gateway
 SG_ RatChaCellBattEgyHi_11_15 : 224|16@1+ (0.006103515625,-2) [-2|1.9999] ""  IOT_Gateway
 SG_ RatChaCellBattEgyHi_11_14 : 208|16@1+ (0.006103515625,-2) [-2|1.9999] ""  IOT_Gateway
 SG_ RatChaCellBattEgyHi_11_13 : 192|16@1+ (0.006103515625,-2) [-2|1.9999] ""  IOT_Gateway
 SG_ RatChaCellBattEgyHi_11_12 : 176|16@1+ (0.006103515625,-2) [-2|1.9999] ""  IOT_Gateway
 SG_ RatChaCellBattEgyHi_11_11 : 160|16@1+ (0.006103515625,-2) [-2|1.9999] ""  IOT_Gateway
 SG_ RatChaCellBattEgyHi_11_10 : 144|16@1+ (0.006103515625,-2) [-2|1.9999] ""  IOT_Gateway
 SG_ RatChaCellBattEgyHi_11_9 : 128|16@1+ (0.006103515625,-2) [-2|1.9999] ""  IOT_Gateway
 SG_ RatChaCellBattEgyHi_11_8 : 112|16@1+ (0.006103515625,-2) [-2|1.9999] ""  IOT_Gateway
 SG_ RatChaCellBattEgyHi_11_7 : 96|16@1+ (0.006103515625,-2) [-2|1.9999] ""  IOT_Gateway
 SG_ RatChaCellBattEgyHi_11_6 : 80|16@1+ (0.006103515625,-2) [-2|1.9999] ""  IOT_Gateway
 SG_ RatChaCellBattEgyHi_11_5 : 64|16@1+ (0.006103515625,-2) [-2|1.9999] ""  IOT_Gateway
 SG_ RatChaCellBattEgyHi_11_4 : 48|16@1+ (0.006103515625,-2) [-2|1.9999] ""  IOT_Gateway
 SG_ RatChaCellBattEgyHi_11_3 : 32|16@1+ (0.006103515625,-2) [-2|1.9999] ""  IOT_Gateway
 SG_ RatChaCellBattEgyHi_11_2 : 16|16@1+ (0.006103515625,-2) [-2|1.9999] ""  IOT_Gateway
 SG_ RatChaCellBattEgyHi_11_1 : 0|16@1+ (0.006103515625,-2) [-2|1.9999] ""  IOT_Gateway

BO_ 124 RatChaCellBattEgyHi_5: 64 BMC
 SG_ RatChaCellBattEgyHi_10_16 : 496|16@1+ (0.006103515625,-2) [-2|1.9999] ""  IOT_Gateway
 SG_ RatChaCellBattEgyHi_10_15 : 480|16@1+ (0.006103515625,-2) [-2|1.9999] ""  IOT_Gateway
 SG_ RatChaCellBattEgyHi_10_14 : 464|16@1+ (0.006103515625,-2) [-2|1.9999] ""  IOT_Gateway
 SG_ RatChaCellBattEgyHi_10_13 : 448|16@1+ (0.006103515625,-2) [-2|1.9999] ""  IOT_Gateway
 SG_ RatChaCellBattEgyHi_10_12 : 432|16@1+ (0.006103515625,-2) [-2|1.9999] ""  IOT_Gateway
 SG_ RatChaCellBattEgyHi_10_11 : 416|16@1+ (0.006103515625,-2) [-2|1.9999] ""  IOT_Gateway
 SG_ RatChaCellBattEgyHi_10_10 : 400|16@1+ (0.006103515625,-2) [-2|1.9999] ""  IOT_Gateway
 SG_ RatChaCellBattEgyHi_10_9 : 384|16@1+ (0.006103515625,-2) [-2|1.9999] ""  IOT_Gateway
 SG_ RatChaCellBattEgyHi_10_8 : 368|16@1+ (0.006103515625,-2) [-2|1.9999] ""  IOT_Gateway
 SG_ RatChaCellBattEgyHi_10_7 : 352|16@1+ (0.006103515625,-2) [-2|1.9999] ""  IOT_Gateway
 SG_ RatChaCellBattEgyHi_10_6 : 336|16@1+ (0.006103515625,-2) [-2|1.9999] ""  IOT_Gateway
 SG_ RatChaCellBattEgyHi_10_5 : 320|16@1+ (0.006103515625,-2) [-2|1.9999] ""  IOT_Gateway
 SG_ RatChaCellBattEgyHi_10_4 : 304|16@1+ (0.006103515625,-2) [-2|1.9999] ""  IOT_Gateway
 SG_ RatChaCellBattEgyHi_10_3 : 288|16@1+ (0.006103515625,-2) [-2|1.9999] ""  IOT_Gateway
 SG_ RatChaCellBattEgyHi_10_2 : 272|16@1+ (0.006103515625,-2) [-2|1.9999] ""  IOT_Gateway
 SG_ RatChaCellBattEgyHi_10_1 : 256|16@1+ (0.006103515625,-2) [-2|1.9999] ""  IOT_Gateway
 SG_ RatChaCellBattEgyHi_9_16 : 240|16@1+ (0.006103515625,-2) [-2|1.9999] ""  IOT_Gateway
 SG_ RatChaCellBattEgyHi_9_15 : 224|16@1+ (0.006103515625,-2) [-2|1.9999] ""  IOT_Gateway
 SG_ RatChaCellBattEgyHi_9_14 : 208|16@1+ (0.006103515625,-2) [-2|1.9999] ""  IOT_Gateway
 SG_ RatChaCellBattEgyHi_9_13 : 192|16@1+ (0.006103515625,-2) [-2|1.9999] ""  IOT_Gateway
 SG_ RatChaCellBattEgyHi_9_12 : 176|16@1+ (0.006103515625,-2) [-2|1.9999] ""  IOT_Gateway
 SG_ RatChaCellBattEgyHi_9_11 : 160|16@1+ (0.006103515625,-2) [-2|1.9999] ""  IOT_Gateway
 SG_ RatChaCellBattEgyHi_9_10 : 144|16@1+ (0.006103515625,-2) [-2|1.9999] ""  IOT_Gateway
 SG_ RatChaCellBattEgyHi_9_9 : 128|16@1+ (0.006103515625,-2) [-2|1.9999] ""  IOT_Gateway
 SG_ RatChaCellBattEgyHi_9_8 : 112|16@1+ (0.006103515625,-2) [-2|1.9999] ""  IOT_Gateway
 SG_ RatChaCellBattEgyHi_9_7 : 96|16@1+ (0.006103515625,-2) [-2|1.9999] ""  IOT_Gateway
 SG_ RatChaCellBattEgyHi_9_6 : 80|16@1+ (0.006103515625,-2) [-2|1.9999] ""  IOT_Gateway
 SG_ RatChaCellBattEgyHi_9_5 : 64|16@1+ (0.006103515625,-2) [-2|1.9999] ""  IOT_Gateway
 SG_ RatChaCellBattEgyHi_9_4 : 48|16@1+ (0.006103515625,-2) [-2|1.9999] ""  IOT_Gateway
 SG_ RatChaCellBattEgyHi_9_3 : 32|16@1+ (0.006103515625,-2) [-2|1.9999] ""  IOT_Gateway
 SG_ RatChaCellBattEgyHi_9_2 : 16|16@1+ (0.006103515625,-2) [-2|1.9999] ""  IOT_Gateway
 SG_ RatChaCellBattEgyHi_9_1 : 0|16@1+ (0.006103515625,-2) [-2|1.9999] ""  IOT_Gateway

BO_ 123 RatChaCellBattEgyHi_4: 64 BMC
 SG_ RatChaCellBattEgyHi_8_16 : 496|16@1+ (0.006103515625,-2) [-2|1.9999] ""  IOT_Gateway
 SG_ RatChaCellBattEgyHi_8_15 : 480|16@1+ (0.006103515625,-2) [-2|1.9999] ""  IOT_Gateway
 SG_ RatChaCellBattEgyHi_8_14 : 464|16@1+ (0.006103515625,-2) [-2|1.9999] ""  IOT_Gateway
 SG_ RatChaCellBattEgyHi_8_13 : 448|16@1+ (0.006103515625,-2) [-2|1.9999] ""  IOT_Gateway
 SG_ RatChaCellBattEgyHi_8_12 : 432|16@1+ (0.006103515625,-2) [-2|1.9999] ""  IOT_Gateway
 SG_ RatChaCellBattEgyHi_8_11 : 416|16@1+ (0.006103515625,-2) [-2|1.9999] ""  IOT_Gateway
 SG_ RatChaCellBattEgyHi_8_10 : 400|16@1+ (0.006103515625,-2) [-2|1.9999] ""  IOT_Gateway
 SG_ RatChaCellBattEgyHi_8_9 : 384|16@1+ (0.006103515625,-2) [-2|1.9999] ""  IOT_Gateway
 SG_ RatChaCellBattEgyHi_8_8 : 368|16@1+ (0.006103515625,-2) [-2|1.9999] ""  IOT_Gateway
 SG_ RatChaCellBattEgyHi_8_7 : 352|16@1+ (0.006103515625,-2) [-2|1.9999] ""  IOT_Gateway
 SG_ RatChaCellBattEgyHi_8_6 : 336|16@1+ (0.006103515625,-2) [-2|1.9999] ""  IOT_Gateway
 SG_ RatChaCellBattEgyHi_8_5 : 320|16@1+ (0.006103515625,-2) [-2|1.9999] ""  IOT_Gateway
 SG_ RatChaCellBattEgyHi_8_4 : 304|16@1+ (0.006103515625,-2) [-2|1.9999] ""  IOT_Gateway
 SG_ RatChaCellBattEgyHi_8_3 : 288|16@1+ (0.006103515625,-2) [-2|1.9999] ""  IOT_Gateway
 SG_ RatChaCellBattEgyHi_8_2 : 272|16@1+ (0.006103515625,-2) [-2|1.9999] ""  IOT_Gateway
 SG_ RatChaCellBattEgyHi_8_1 : 256|16@1+ (0.006103515625,-2) [-2|1.9999] ""  IOT_Gateway
 SG_ RatChaCellBattEgyHi_7_16 : 240|16@1+ (0.006103515625,-2) [-2|1.9999] ""  IOT_Gateway
 SG_ RatChaCellBattEgyHi_7_15 : 224|16@1+ (0.006103515625,-2) [-2|1.9999] ""  IOT_Gateway
 SG_ RatChaCellBattEgyHi_7_14 : 208|16@1+ (0.006103515625,-2) [-2|1.9999] ""  IOT_Gateway
 SG_ RatChaCellBattEgyHi_7_13 : 192|16@1+ (0.006103515625,-2) [-2|1.9999] ""  IOT_Gateway
 SG_ RatChaCellBattEgyHi_7_12 : 176|16@1+ (0.006103515625,-2) [-2|1.9999] ""  IOT_Gateway
 SG_ RatChaCellBattEgyHi_7_11 : 160|16@1+ (0.006103515625,-2) [-2|1.9999] ""  IOT_Gateway
 SG_ RatChaCellBattEgyHi_7_10 : 144|16@1+ (0.006103515625,-2) [-2|1.9999] ""  IOT_Gateway
 SG_ RatChaCellBattEgyHi_7_9 : 128|16@1+ (0.006103515625,-2) [-2|1.9999] ""  IOT_Gateway
 SG_ RatChaCellBattEgyHi_7_8 : 112|16@1+ (0.006103515625,-2) [-2|1.9999] ""  IOT_Gateway
 SG_ RatChaCellBattEgyHi_7_7 : 96|16@1+ (0.006103515625,-2) [-2|1.9999] ""  IOT_Gateway
 SG_ RatChaCellBattEgyHi_7_6 : 80|16@1+ (0.006103515625,-2) [-2|1.9999] ""  IOT_Gateway
 SG_ RatChaCellBattEgyHi_7_5 : 64|16@1+ (0.006103515625,-2) [-2|1.9999] ""  IOT_Gateway
 SG_ RatChaCellBattEgyHi_7_4 : 48|16@1+ (0.006103515625,-2) [-2|1.9999] ""  IOT_Gateway
 SG_ RatChaCellBattEgyHi_7_3 : 32|16@1+ (0.006103515625,-2) [-2|1.9999] ""  IOT_Gateway
 SG_ RatChaCellBattEgyHi_7_2 : 16|16@1+ (0.006103515625,-2) [-2|1.9999] ""  IOT_Gateway
 SG_ RatChaCellBattEgyHi_7_1 : 0|16@1+ (0.006103515625,-2) [-2|1.9999] ""  IOT_Gateway

BO_ 122 RatChaCellBattEgyHi_3: 64 BMC
 SG_ RatChaCellBattEgyHi_6_16 : 496|16@1+ (0.006103515625,-2) [-2|1.9999] ""  IOT_Gateway
 SG_ RatChaCellBattEgyHi_6_15 : 480|16@1+ (0.006103515625,-2) [-2|1.9999] ""  IOT_Gateway
 SG_ RatChaCellBattEgyHi_6_14 : 464|16@1+ (0.006103515625,-2) [-2|1.9999] ""  IOT_Gateway
 SG_ RatChaCellBattEgyHi_6_13 : 448|16@1+ (0.006103515625,-2) [-2|1.9999] ""  IOT_Gateway
 SG_ RatChaCellBattEgyHi_6_12 : 432|16@1+ (0.006103515625,-2) [-2|1.9999] ""  IOT_Gateway
 SG_ RatChaCellBattEgyHi_6_11 : 416|16@1+ (0.006103515625,-2) [-2|1.9999] ""  IOT_Gateway
 SG_ RatChaCellBattEgyHi_6_10 : 400|16@1+ (0.006103515625,-2) [-2|1.9999] ""  IOT_Gateway
 SG_ RatChaCellBattEgyHi_6_9 : 384|16@1+ (0.006103515625,-2) [-2|1.9999] ""  IOT_Gateway
 SG_ RatChaCellBattEgyHi_6_8 : 368|16@1+ (0.006103515625,-2) [-2|1.9999] ""  IOT_Gateway
 SG_ RatChaCellBattEgyHi_6_7 : 352|16@1+ (0.006103515625,-2) [-2|1.9999] ""  IOT_Gateway
 SG_ RatChaCellBattEgyHi_6_6 : 336|16@1+ (0.006103515625,-2) [-2|1.9999] ""  IOT_Gateway
 SG_ RatChaCellBattEgyHi_6_5 : 320|16@1+ (0.006103515625,-2) [-2|1.9999] ""  IOT_Gateway
 SG_ RatChaCellBattEgyHi_6_4 : 304|16@1+ (0.006103515625,-2) [-2|1.9999] ""  IOT_Gateway
 SG_ RatChaCellBattEgyHi_6_3 : 288|16@1+ (0.006103515625,-2) [-2|1.9999] ""  IOT_Gateway
 SG_ RatChaCellBattEgyHi_6_2 : 272|16@1+ (0.006103515625,-2) [-2|1.9999] ""  IOT_Gateway
 SG_ RatChaCellBattEgyHi_6_1 : 256|16@1+ (0.006103515625,-2) [-2|1.9999] ""  IOT_Gateway
 SG_ RatChaCellBattEgyHi_5_16 : 240|16@1+ (0.006103515625,-2) [-2|1.9999] ""  IOT_Gateway
 SG_ RatChaCellBattEgyHi_5_15 : 224|16@1+ (0.006103515625,-2) [-2|1.9999] ""  IOT_Gateway
 SG_ RatChaCellBattEgyHi_5_14 : 208|16@1+ (0.006103515625,-2) [-2|1.9999] ""  IOT_Gateway
 SG_ RatChaCellBattEgyHi_5_13 : 192|16@1+ (0.006103515625,-2) [-2|1.9999] ""  IOT_Gateway
 SG_ RatChaCellBattEgyHi_5_12 : 176|16@1+ (0.006103515625,-2) [-2|1.9999] ""  IOT_Gateway
 SG_ RatChaCellBattEgyHi_5_11 : 160|16@1+ (0.006103515625,-2) [-2|1.9999] ""  IOT_Gateway
 SG_ RatChaCellBattEgyHi_5_10 : 144|16@1+ (0.006103515625,-2) [-2|1.9999] ""  IOT_Gateway
 SG_ RatChaCellBattEgyHi_5_9 : 128|16@1+ (0.006103515625,-2) [-2|1.9999] ""  IOT_Gateway
 SG_ RatChaCellBattEgyHi_5_8 : 112|16@1+ (0.006103515625,-2) [-2|1.9999] ""  IOT_Gateway
 SG_ RatChaCellBattEgyHi_5_7 : 96|16@1+ (0.006103515625,-2) [-2|1.9999] ""  IOT_Gateway
 SG_ RatChaCellBattEgyHi_5_6 : 80|16@1+ (0.006103515625,-2) [-2|1.9999] ""  IOT_Gateway
 SG_ RatChaCellBattEgyHi_5_5 : 64|16@1+ (0.006103515625,-2) [-2|1.9999] ""  IOT_Gateway
 SG_ RatChaCellBattEgyHi_5_4 : 48|16@1+ (0.006103515625,-2) [-2|1.9999] ""  IOT_Gateway
 SG_ RatChaCellBattEgyHi_5_3 : 32|16@1+ (0.006103515625,-2) [-2|1.9999] ""  IOT_Gateway
 SG_ RatChaCellBattEgyHi_5_2 : 16|16@1+ (0.006103515625,-2) [-2|1.9999] ""  IOT_Gateway
 SG_ RatChaCellBattEgyHi_5_1 : 0|16@1+ (0.006103515625,-2) [-2|1.9999] ""  IOT_Gateway

BO_ 121 RatChaCellBattEgyHi_2: 64 BMC
 SG_ RatChaCellBattEgyHi_4_16 : 496|16@1+ (0.006103515625,-2) [-2|1.9999] ""  IOT_Gateway
 SG_ RatChaCellBattEgyHi_4_15 : 480|16@1+ (0.006103515625,-2) [-2|1.9999] ""  IOT_Gateway
 SG_ RatChaCellBattEgyHi_4_14 : 464|16@1+ (0.006103515625,-2) [-2|1.9999] ""  IOT_Gateway
 SG_ RatChaCellBattEgyHi_4_13 : 448|16@1+ (0.006103515625,-2) [-2|1.9999] ""  IOT_Gateway
 SG_ RatChaCellBattEgyHi_4_12 : 432|16@1+ (0.006103515625,-2) [-2|1.9999] ""  IOT_Gateway
 SG_ RatChaCellBattEgyHi_4_11 : 416|16@1+ (0.006103515625,-2) [-2|1.9999] ""  IOT_Gateway
 SG_ RatChaCellBattEgyHi_4_10 : 400|16@1+ (0.006103515625,-2) [-2|1.9999] ""  IOT_Gateway
 SG_ RatChaCellBattEgyHi_4_9 : 384|16@1+ (0.006103515625,-2) [-2|1.9999] ""  IOT_Gateway
 SG_ RatChaCellBattEgyHi_4_8 : 368|16@1+ (0.006103515625,-2) [-2|1.9999] ""  IOT_Gateway
 SG_ RatChaCellBattEgyHi_4_7 : 352|16@1+ (0.006103515625,-2) [-2|1.9999] ""  IOT_Gateway
 SG_ RatChaCellBattEgyHi_4_6 : 336|16@1+ (0.006103515625,-2) [-2|1.9999] ""  IOT_Gateway
 SG_ RatChaCellBattEgyHi_4_5 : 320|16@1+ (0.006103515625,-2) [-2|1.9999] ""  IOT_Gateway
 SG_ RatChaCellBattEgyHi_4_4 : 304|16@1+ (0.006103515625,-2) [-2|1.9999] ""  IOT_Gateway
 SG_ RatChaCellBattEgyHi_4_3 : 288|16@1+ (0.006103515625,-2) [-2|1.9999] ""  IOT_Gateway
 SG_ RatChaCellBattEgyHi_4_2 : 272|16@1+ (0.006103515625,-2) [-2|1.9999] ""  IOT_Gateway
 SG_ RatChaCellBattEgyHi_4_1 : 256|16@1+ (0.006103515625,-2) [-2|1.9999] ""  IOT_Gateway
 SG_ RatChaCellBattEgyHi_3_16 : 240|16@1+ (0.006103515625,-2) [-2|1.9999] ""  IOT_Gateway
 SG_ RatChaCellBattEgyHi_3_15 : 224|16@1+ (0.006103515625,-2) [-2|1.9999] ""  IOT_Gateway
 SG_ RatChaCellBattEgyHi_3_14 : 208|16@1+ (0.006103515625,-2) [-2|1.9999] ""  IOT_Gateway
 SG_ RatChaCellBattEgyHi_3_13 : 192|16@1+ (0.006103515625,-2) [-2|1.9999] ""  IOT_Gateway
 SG_ RatChaCellBattEgyHi_3_12 : 176|16@1+ (0.006103515625,-2) [-2|1.9999] ""  IOT_Gateway
 SG_ RatChaCellBattEgyHi_3_11 : 160|16@1+ (0.006103515625,-2) [-2|1.9999] ""  IOT_Gateway
 SG_ RatChaCellBattEgyHi_3_10 : 144|16@1+ (0.006103515625,-2) [-2|1.9999] ""  IOT_Gateway
 SG_ RatChaCellBattEgyHi_3_9 : 128|16@1+ (0.006103515625,-2) [-2|1.9999] ""  IOT_Gateway
 SG_ RatChaCellBattEgyHi_3_8 : 112|16@1+ (0.006103515625,-2) [-2|1.9999] ""  IOT_Gateway
 SG_ RatChaCellBattEgyHi_3_7 : 96|16@1+ (0.006103515625,-2) [-2|1.9999] ""  IOT_Gateway
 SG_ RatChaCellBattEgyHi_3_6 : 80|16@1+ (0.006103515625,-2) [-2|1.9999] ""  IOT_Gateway
 SG_ RatChaCellBattEgyHi_3_5 : 64|16@1+ (0.006103515625,-2) [-2|1.9999] ""  IOT_Gateway
 SG_ RatChaCellBattEgyHi_3_4 : 48|16@1+ (0.006103515625,-2) [-2|1.9999] ""  IOT_Gateway
 SG_ RatChaCellBattEgyHi_3_3 : 32|16@1+ (0.006103515625,-2) [-2|1.9999] ""  IOT_Gateway
 SG_ RatChaCellBattEgyHi_3_2 : 16|16@1+ (0.006103515625,-2) [-2|1.9999] ""  IOT_Gateway
 SG_ RatChaCellBattEgyHi_3_1 : 0|16@1+ (0.006103515625,-2) [-2|1.9999] ""  IOT_Gateway

BO_ 120 RatChaCellBattEgyHi_1: 64 BMC
 SG_ RatChaCellBattEgyHi_2_16 : 496|16@1+ (0.006103515625,-2) [-2|1.9999] ""  IOT_Gateway
 SG_ RatChaCellBattEgyHi_2_15 : 480|16@1+ (0.006103515625,-2) [-2|1.9999] ""  IOT_Gateway
 SG_ RatChaCellBattEgyHi_2_14 : 464|16@1+ (0.006103515625,-2) [-2|1.9999] ""  IOT_Gateway
 SG_ RatChaCellBattEgyHi_2_13 : 448|16@1+ (0.006103515625,-2) [-2|1.9999] ""  IOT_Gateway
 SG_ RatChaCellBattEgyHi_2_12 : 432|16@1+ (0.006103515625,-2) [-2|1.9999] ""  IOT_Gateway
 SG_ RatChaCellBattEgyHi_2_11 : 416|16@1+ (0.006103515625,-2) [-2|1.9999] ""  IOT_Gateway
 SG_ RatChaCellBattEgyHi_2_10 : 400|16@1+ (0.006103515625,-2) [-2|1.9999] ""  IOT_Gateway
 SG_ RatChaCellBattEgyHi_2_9 : 384|16@1+ (0.006103515625,-2) [-2|1.9999] ""  IOT_Gateway
 SG_ RatChaCellBattEgyHi_2_8 : 368|16@1+ (0.006103515625,-2) [-2|1.9999] ""  IOT_Gateway
 SG_ RatChaCellBattEgyHi_2_7 : 352|16@1+ (0.006103515625,-2) [-2|1.9999] ""  IOT_Gateway
 SG_ RatChaCellBattEgyHi_2_6 : 336|16@1+ (0.006103515625,-2) [-2|1.9999] ""  IOT_Gateway
 SG_ RatChaCellBattEgyHi_2_5 : 320|16@1+ (0.006103515625,-2) [-2|1.9999] ""  IOT_Gateway
 SG_ RatChaCellBattEgyHi_2_4 : 304|16@1+ (0.006103515625,-2) [-2|1.9999] ""  IOT_Gateway
 SG_ RatChaCellBattEgyHi_2_3 : 288|16@1+ (0.006103515625,-2) [-2|1.9999] ""  IOT_Gateway
 SG_ RatChaCellBattEgyHi_2_2 : 272|16@1+ (0.006103515625,-2) [-2|1.9999] ""  IOT_Gateway
 SG_ RatChaCellBattEgyHi_2_1 : 256|16@1+ (0.006103515625,-2) [-2|1.9999] ""  IOT_Gateway
 SG_ RatChaCellBattEgyHi_1_16 : 240|16@1+ (0.006103515625,-2) [-2|1.9999] ""  IOT_Gateway
 SG_ RatChaCellBattEgyHi_1_15 : 224|16@1+ (0.006103515625,-2) [-2|1.9999] ""  IOT_Gateway
 SG_ RatChaCellBattEgyHi_1_14 : 208|16@1+ (0.006103515625,-2) [-2|1.9999] ""  IOT_Gateway
 SG_ RatChaCellBattEgyHi_1_13 : 192|16@1+ (0.006103515625,-2) [-2|1.9999] ""  IOT_Gateway
 SG_ RatChaCellBattEgyHi_1_12 : 176|16@1+ (0.006103515625,-2) [-2|1.9999] ""  IOT_Gateway
 SG_ RatChaCellBattEgyHi_1_11 : 160|16@1+ (0.006103515625,-2) [-2|1.9999] ""  IOT_Gateway
 SG_ RatChaCellBattEgyHi_1_10 : 144|16@1+ (0.006103515625,-2) [-2|1.9999] ""  IOT_Gateway
 SG_ RatChaCellBattEgyHi_1_9 : 128|16@1+ (0.006103515625,-2) [-2|1.9999] ""  IOT_Gateway
 SG_ RatChaCellBattEgyHi_1_8 : 112|16@1+ (0.006103515625,-2) [-2|1.9999] ""  IOT_Gateway
 SG_ RatChaCellBattEgyHi_1_7 : 96|16@1+ (0.006103515625,-2) [-2|1.9999] ""  IOT_Gateway
 SG_ RatChaCellBattEgyHi_1_6 : 80|16@1+ (0.006103515625,-2) [-2|1.9999] ""  IOT_Gateway
 SG_ RatChaCellBattEgyHi_1_5 : 64|16@1+ (0.006103515625,-2) [-2|1.9999] ""  IOT_Gateway
 SG_ RatChaCellBattEgyHi_1_4 : 48|16@1+ (0.006103515625,-2) [-2|1.9999] ""  IOT_Gateway
 SG_ RatChaCellBattEgyHi_1_3 : 32|16@1+ (0.006103515625,-2) [-2|1.9999] ""  IOT_Gateway
 SG_ RatChaCellBattEgyHi_1_2 : 16|16@1+ (0.006103515625,-2) [-2|1.9999] ""  IOT_Gateway
 SG_ RatChaCellBattEgyHi_1_1 : 0|16@1+ (0.006103515625,-2) [-2|1.9999] ""  IOT_Gateway

BO_ 119 RatChaCellBattPwrHi_8: 64 BMC
 SG_ RatChaCellBattPwrHi_16_16 : 496|16@1+ (0.0030517578125,0) [0|199.996948242188] ""  IOT_Gateway
 SG_ RatChaCellBattPwrHi_16_15 : 480|16@1+ (0.0030517578125,0) [0|199.996948242188] ""  IOT_Gateway
 SG_ RatChaCellBattPwrHi_16_14 : 464|16@1+ (0.0030517578125,0) [0|199.996948242188] ""  IOT_Gateway
 SG_ RatChaCellBattPwrHi_16_13 : 448|16@1+ (0.0030517578125,0) [0|199.996948242188] ""  IOT_Gateway
 SG_ RatChaCellBattPwrHi_16_12 : 432|16@1+ (0.0030517578125,0) [0|199.996948242188] ""  IOT_Gateway
 SG_ RatChaCellBattPwrHi_16_11 : 416|16@1+ (0.0030517578125,0) [0|199.996948242188] ""  IOT_Gateway
 SG_ RatChaCellBattPwrHi_16_10 : 400|16@1+ (0.0030517578125,0) [0|199.996948242188] ""  IOT_Gateway
 SG_ RatChaCellBattPwrHi_16_9 : 384|16@1+ (0.0030517578125,0) [0|199.996948242188] ""  IOT_Gateway
 SG_ RatChaCellBattPwrHi_16_8 : 368|16@1+ (0.0030517578125,0) [0|199.996948242188] ""  IOT_Gateway
 SG_ RatChaCellBattPwrHi_16_7 : 352|16@1+ (0.0030517578125,0) [0|199.996948242188] ""  IOT_Gateway
 SG_ RatChaCellBattPwrHi_16_6 : 336|16@1+ (0.0030517578125,0) [0|199.996948242188] ""  IOT_Gateway
 SG_ RatChaCellBattPwrHi_16_5 : 320|16@1+ (0.0030517578125,0) [0|199.996948242188] ""  IOT_Gateway
 SG_ RatChaCellBattPwrHi_16_4 : 304|16@1+ (0.0030517578125,0) [0|199.996948242188] ""  IOT_Gateway
 SG_ RatChaCellBattPwrHi_16_3 : 288|16@1+ (0.0030517578125,0) [0|199.996948242188] ""  IOT_Gateway
 SG_ RatChaCellBattPwrHi_16_2 : 272|16@1+ (0.0030517578125,0) [0|199.996948242188] ""  IOT_Gateway
 SG_ RatChaCellBattPwrHi_16_1 : 256|16@1+ (0.0030517578125,0) [0|199.996948242188] ""  IOT_Gateway
 SG_ RatChaCellBattPwrHi_15_16 : 240|16@1+ (0.0030517578125,0) [0|199.996948242188] ""  IOT_Gateway
 SG_ RatChaCellBattPwrHi_15_15 : 224|16@1+ (0.0030517578125,0) [0|199.996948242188] ""  IOT_Gateway
 SG_ RatChaCellBattPwrHi_15_14 : 208|16@1+ (0.0030517578125,0) [0|199.996948242188] ""  IOT_Gateway
 SG_ RatChaCellBattPwrHi_15_13 : 192|16@1+ (0.0030517578125,0) [0|199.996948242188] ""  IOT_Gateway
 SG_ RatChaCellBattPwrHi_15_12 : 176|16@1+ (0.0030517578125,0) [0|199.996948242188] ""  IOT_Gateway
 SG_ RatChaCellBattPwrHi_15_11 : 160|16@1+ (0.0030517578125,0) [0|199.996948242188] ""  IOT_Gateway
 SG_ RatChaCellBattPwrHi_15_10 : 144|16@1+ (0.0030517578125,0) [0|199.996948242188] ""  IOT_Gateway
 SG_ RatChaCellBattPwrHi_15_9 : 128|16@1+ (0.0030517578125,0) [0|199.996948242188] ""  IOT_Gateway
 SG_ RatChaCellBattPwrHi_15_8 : 112|16@1+ (0.0030517578125,0) [0|199.996948242188] ""  IOT_Gateway
 SG_ RatChaCellBattPwrHi_15_7 : 96|16@1+ (0.0030517578125,0) [0|199.996948242188] ""  IOT_Gateway
 SG_ RatChaCellBattPwrHi_15_6 : 80|16@1+ (0.0030517578125,0) [0|199.996948242188] ""  IOT_Gateway
 SG_ RatChaCellBattPwrHi_15_5 : 64|16@1+ (0.0030517578125,0) [0|199.996948242188] ""  IOT_Gateway
 SG_ RatChaCellBattPwrHi_15_4 : 48|16@1+ (0.0030517578125,0) [0|199.996948242188] ""  IOT_Gateway
 SG_ RatChaCellBattPwrHi_15_3 : 32|16@1+ (0.0030517578125,0) [0|199.996948242188] ""  IOT_Gateway
 SG_ RatChaCellBattPwrHi_15_2 : 16|16@1+ (0.0030517578125,0) [0|199.996948242188] ""  IOT_Gateway
 SG_ RatChaCellBattPwrHi_15_1 : 0|16@1+ (0.0030517578125,0) [0|199.996948242188] ""  IOT_Gateway

BO_ 118 RatChaCellBattPwrHi_7: 64 BMC
 SG_ RatChaCellBattPwrHi_14_16 : 496|16@1+ (0.0030517578125,0) [0|199.996948242188] ""  IOT_Gateway
 SG_ RatChaCellBattPwrHi_14_15 : 480|16@1+ (0.0030517578125,0) [0|199.996948242188] ""  IOT_Gateway
 SG_ RatChaCellBattPwrHi_14_14 : 464|16@1+ (0.0030517578125,0) [0|199.996948242188] ""  IOT_Gateway
 SG_ RatChaCellBattPwrHi_14_13 : 448|16@1+ (0.0030517578125,0) [0|199.996948242188] ""  IOT_Gateway
 SG_ RatChaCellBattPwrHi_14_12 : 432|16@1+ (0.0030517578125,0) [0|199.996948242188] ""  IOT_Gateway
 SG_ RatChaCellBattPwrHi_14_11 : 416|16@1+ (0.0030517578125,0) [0|199.996948242188] ""  IOT_Gateway
 SG_ RatChaCellBattPwrHi_14_10 : 400|16@1+ (0.0030517578125,0) [0|199.996948242188] ""  IOT_Gateway
 SG_ RatChaCellBattPwrHi_14_9 : 384|16@1+ (0.0030517578125,0) [0|199.996948242188] ""  IOT_Gateway
 SG_ RatChaCellBattPwrHi_14_8 : 368|16@1+ (0.0030517578125,0) [0|199.996948242188] ""  IOT_Gateway
 SG_ RatChaCellBattPwrHi_14_7 : 352|16@1+ (0.0030517578125,0) [0|199.996948242188] ""  IOT_Gateway
 SG_ RatChaCellBattPwrHi_14_6 : 336|16@1+ (0.0030517578125,0) [0|199.996948242188] ""  IOT_Gateway
 SG_ RatChaCellBattPwrHi_14_5 : 320|16@1+ (0.0030517578125,0) [0|199.996948242188] ""  IOT_Gateway
 SG_ RatChaCellBattPwrHi_14_4 : 304|16@1+ (0.0030517578125,0) [0|199.996948242188] ""  IOT_Gateway
 SG_ RatChaCellBattPwrHi_14_3 : 288|16@1+ (0.0030517578125,0) [0|199.996948242188] ""  IOT_Gateway
 SG_ RatChaCellBattPwrHi_14_2 : 272|16@1+ (0.0030517578125,0) [0|199.996948242188] ""  IOT_Gateway
 SG_ RatChaCellBattPwrHi_14_1 : 256|16@1+ (0.0030517578125,0) [0|199.996948242188] ""  IOT_Gateway
 SG_ RatChaCellBattPwrHi_13_16 : 240|16@1+ (0.0030517578125,0) [0|199.996948242188] ""  IOT_Gateway
 SG_ RatChaCellBattPwrHi_13_15 : 224|16@1+ (0.0030517578125,0) [0|199.996948242188] ""  IOT_Gateway
 SG_ RatChaCellBattPwrHi_13_14 : 208|16@1+ (0.0030517578125,0) [0|199.996948242188] ""  IOT_Gateway
 SG_ RatChaCellBattPwrHi_13_13 : 192|16@1+ (0.0030517578125,0) [0|199.996948242188] ""  IOT_Gateway
 SG_ RatChaCellBattPwrHi_13_12 : 176|16@1+ (0.0030517578125,0) [0|199.996948242188] ""  IOT_Gateway
 SG_ RatChaCellBattPwrHi_13_11 : 160|16@1+ (0.0030517578125,0) [0|199.996948242188] ""  IOT_Gateway
 SG_ RatChaCellBattPwrHi_13_10 : 144|16@1+ (0.0030517578125,0) [0|199.996948242188] ""  IOT_Gateway
 SG_ RatChaCellBattPwrHi_13_9 : 128|16@1+ (0.0030517578125,0) [0|199.996948242188] ""  IOT_Gateway
 SG_ RatChaCellBattPwrHi_13_8 : 112|16@1+ (0.0030517578125,0) [0|199.996948242188] ""  IOT_Gateway
 SG_ RatChaCellBattPwrHi_13_7 : 96|16@1+ (0.0030517578125,0) [0|199.996948242188] ""  IOT_Gateway
 SG_ RatChaCellBattPwrHi_13_6 : 80|16@1+ (0.0030517578125,0) [0|199.996948242188] ""  IOT_Gateway
 SG_ RatChaCellBattPwrHi_13_5 : 64|16@1+ (0.0030517578125,0) [0|199.996948242188] ""  IOT_Gateway
 SG_ RatChaCellBattPwrHi_13_4 : 48|16@1+ (0.0030517578125,0) [0|199.996948242188] ""  IOT_Gateway
 SG_ RatChaCellBattPwrHi_13_3 : 32|16@1+ (0.0030517578125,0) [0|199.996948242188] ""  IOT_Gateway
 SG_ RatChaCellBattPwrHi_13_2 : 16|16@1+ (0.0030517578125,0) [0|199.996948242188] ""  IOT_Gateway
 SG_ RatChaCellBattPwrHi_13_1 : 0|16@1+ (0.0030517578125,0) [0|199.996948242188] ""  IOT_Gateway

BO_ 117 RatChaCellBattPwrHi_6: 64 BMC
 SG_ RatChaCellBattPwrHi_12_16 : 496|16@1+ (0.0030517578125,0) [0|199.996948242188] ""  IOT_Gateway
 SG_ RatChaCellBattPwrHi_12_15 : 480|16@1+ (0.0030517578125,0) [0|199.996948242188] ""  IOT_Gateway
 SG_ RatChaCellBattPwrHi_12_14 : 464|16@1+ (0.0030517578125,0) [0|199.996948242188] ""  IOT_Gateway
 SG_ RatChaCellBattPwrHi_12_13 : 448|16@1+ (0.0030517578125,0) [0|199.996948242188] ""  IOT_Gateway
 SG_ RatChaCellBattPwrHi_12_12 : 432|16@1+ (0.0030517578125,0) [0|199.996948242188] ""  IOT_Gateway
 SG_ RatChaCellBattPwrHi_12_11 : 416|16@1+ (0.0030517578125,0) [0|199.996948242188] ""  IOT_Gateway
 SG_ RatChaCellBattPwrHi_12_10 : 400|16@1+ (0.0030517578125,0) [0|199.996948242188] ""  IOT_Gateway
 SG_ RatChaCellBattPwrHi_12_9 : 384|16@1+ (0.0030517578125,0) [0|199.996948242188] ""  IOT_Gateway
 SG_ RatChaCellBattPwrHi_12_8 : 368|16@1+ (0.0030517578125,0) [0|199.996948242188] ""  IOT_Gateway
 SG_ RatChaCellBattPwrHi_12_7 : 352|16@1+ (0.0030517578125,0) [0|199.996948242188] ""  IOT_Gateway
 SG_ RatChaCellBattPwrHi_12_6 : 336|16@1+ (0.0030517578125,0) [0|199.996948242188] ""  IOT_Gateway
 SG_ RatChaCellBattPwrHi_12_5 : 320|16@1+ (0.0030517578125,0) [0|199.996948242188] ""  IOT_Gateway
 SG_ RatChaCellBattPwrHi_12_4 : 304|16@1+ (0.0030517578125,0) [0|199.996948242188] ""  IOT_Gateway
 SG_ RatChaCellBattPwrHi_12_3 : 288|16@1+ (0.0030517578125,0) [0|199.996948242188] ""  IOT_Gateway
 SG_ RatChaCellBattPwrHi_12_2 : 272|16@1+ (0.0030517578125,0) [0|199.996948242188] ""  IOT_Gateway
 SG_ RatChaCellBattPwrHi_12_1 : 256|16@1+ (0.0030517578125,0) [0|199.996948242188] ""  IOT_Gateway
 SG_ RatChaCellBattPwrHi_11_16 : 240|16@1+ (0.0030517578125,0) [0|199.996948242188] ""  IOT_Gateway
 SG_ RatChaCellBattPwrHi_11_15 : 224|16@1+ (0.0030517578125,0) [0|199.996948242188] ""  IOT_Gateway
 SG_ RatChaCellBattPwrHi_11_14 : 208|16@1+ (0.0030517578125,0) [0|199.996948242188] ""  IOT_Gateway
 SG_ RatChaCellBattPwrHi_11_13 : 192|16@1+ (0.0030517578125,0) [0|199.996948242188] ""  IOT_Gateway
 SG_ RatChaCellBattPwrHi_11_12 : 176|16@1+ (0.0030517578125,0) [0|199.996948242188] ""  IOT_Gateway
 SG_ RatChaCellBattPwrHi_11_11 : 160|16@1+ (0.0030517578125,0) [0|199.996948242188] ""  IOT_Gateway
 SG_ RatChaCellBattPwrHi_11_10 : 144|16@1+ (0.0030517578125,0) [0|199.996948242188] ""  IOT_Gateway
 SG_ RatChaCellBattPwrHi_11_9 : 128|16@1+ (0.0030517578125,0) [0|199.996948242188] ""  IOT_Gateway
 SG_ RatChaCellBattPwrHi_11_8 : 112|16@1+ (0.0030517578125,0) [0|199.996948242188] ""  IOT_Gateway
 SG_ RatChaCellBattPwrHi_11_7 : 96|16@1+ (0.0030517578125,0) [0|199.996948242188] ""  IOT_Gateway
 SG_ RatChaCellBattPwrHi_11_6 : 80|16@1+ (0.0030517578125,0) [0|199.996948242188] ""  IOT_Gateway
 SG_ RatChaCellBattPwrHi_11_5 : 64|16@1+ (0.0030517578125,0) [0|199.996948242188] ""  IOT_Gateway
 SG_ RatChaCellBattPwrHi_11_4 : 48|16@1+ (0.0030517578125,0) [0|199.996948242188] ""  IOT_Gateway
 SG_ RatChaCellBattPwrHi_11_3 : 32|16@1+ (0.0030517578125,0) [0|199.996948242188] ""  IOT_Gateway
 SG_ RatChaCellBattPwrHi_11_2 : 16|16@1+ (0.0030517578125,0) [0|199.996948242188] ""  IOT_Gateway
 SG_ RatChaCellBattPwrHi_11_1 : 0|16@1+ (0.0030517578125,0) [0|199.996948242188] ""  IOT_Gateway

BO_ 116 RatChaCellBattPwrHi_5: 64 BMC
 SG_ RatChaCellBattPwrHi_10_16 : 496|16@1+ (0.0030517578125,0) [0|199.996948242188] ""  IOT_Gateway
 SG_ RatChaCellBattPwrHi_10_15 : 480|16@1+ (0.0030517578125,0) [0|199.996948242188] ""  IOT_Gateway
 SG_ RatChaCellBattPwrHi_10_14 : 464|16@1+ (0.0030517578125,0) [0|199.996948242188] ""  IOT_Gateway
 SG_ RatChaCellBattPwrHi_10_13 : 448|16@1+ (0.0030517578125,0) [0|199.996948242188] ""  IOT_Gateway
 SG_ RatChaCellBattPwrHi_10_12 : 432|16@1+ (0.0030517578125,0) [0|199.996948242188] ""  IOT_Gateway
 SG_ RatChaCellBattPwrHi_10_11 : 416|16@1+ (0.0030517578125,0) [0|199.996948242188] ""  IOT_Gateway
 SG_ RatChaCellBattPwrHi_10_10 : 400|16@1+ (0.0030517578125,0) [0|199.996948242188] ""  IOT_Gateway
 SG_ RatChaCellBattPwrHi_10_9 : 384|16@1+ (0.0030517578125,0) [0|199.996948242188] ""  IOT_Gateway
 SG_ RatChaCellBattPwrHi_10_8 : 368|16@1+ (0.0030517578125,0) [0|199.996948242188] ""  IOT_Gateway
 SG_ RatChaCellBattPwrHi_10_7 : 352|16@1+ (0.0030517578125,0) [0|199.996948242188] ""  IOT_Gateway
 SG_ RatChaCellBattPwrHi_10_6 : 336|16@1+ (0.0030517578125,0) [0|199.996948242188] ""  IOT_Gateway
 SG_ RatChaCellBattPwrHi_10_5 : 320|16@1+ (0.0030517578125,0) [0|199.996948242188] ""  IOT_Gateway
 SG_ RatChaCellBattPwrHi_10_4 : 304|16@1+ (0.0030517578125,0) [0|199.996948242188] ""  IOT_Gateway
 SG_ RatChaCellBattPwrHi_10_3 : 288|16@1+ (0.0030517578125,0) [0|199.996948242188] ""  IOT_Gateway
 SG_ RatChaCellBattPwrHi_10_2 : 272|16@1+ (0.0030517578125,0) [0|199.996948242188] ""  IOT_Gateway
 SG_ RatChaCellBattPwrHi_10_1 : 256|16@1+ (0.0030517578125,0) [0|199.996948242188] ""  IOT_Gateway
 SG_ RatChaCellBattPwrHi_9_16 : 240|16@1+ (0.0030517578125,0) [0|199.996948242188] ""  IOT_Gateway
 SG_ RatChaCellBattPwrHi_9_15 : 224|16@1+ (0.0030517578125,0) [0|199.996948242188] ""  IOT_Gateway
 SG_ RatChaCellBattPwrHi_9_14 : 208|16@1+ (0.0030517578125,0) [0|199.996948242188] ""  IOT_Gateway
 SG_ RatChaCellBattPwrHi_9_13 : 192|16@1+ (0.0030517578125,0) [0|199.996948242188] ""  IOT_Gateway
 SG_ RatChaCellBattPwrHi_9_12 : 176|16@1+ (0.0030517578125,0) [0|199.996948242188] ""  IOT_Gateway
 SG_ RatChaCellBattPwrHi_9_11 : 160|16@1+ (0.0030517578125,0) [0|199.996948242188] ""  IOT_Gateway
 SG_ RatChaCellBattPwrHi_9_10 : 144|16@1+ (0.0030517578125,0) [0|199.996948242188] ""  IOT_Gateway
 SG_ RatChaCellBattPwrHi_9_9 : 128|16@1+ (0.0030517578125,0) [0|199.996948242188] ""  IOT_Gateway
 SG_ RatChaCellBattPwrHi_9_8 : 112|16@1+ (0.0030517578125,0) [0|199.996948242188] ""  IOT_Gateway
 SG_ RatChaCellBattPwrHi_9_7 : 96|16@1+ (0.0030517578125,0) [0|199.996948242188] ""  IOT_Gateway
 SG_ RatChaCellBattPwrHi_9_6 : 80|16@1+ (0.0030517578125,0) [0|199.996948242188] ""  IOT_Gateway
 SG_ RatChaCellBattPwrHi_9_5 : 64|16@1+ (0.0030517578125,0) [0|199.996948242188] ""  IOT_Gateway
 SG_ RatChaCellBattPwrHi_9_4 : 48|16@1+ (0.0030517578125,0) [0|199.996948242188] ""  IOT_Gateway
 SG_ RatChaCellBattPwrHi_9_3 : 32|16@1+ (0.0030517578125,0) [0|199.996948242188] ""  IOT_Gateway
 SG_ RatChaCellBattPwrHi_9_2 : 16|16@1+ (0.0030517578125,0) [0|199.996948242188] ""  IOT_Gateway
 SG_ RatChaCellBattPwrHi_9_1 : 0|16@1+ (0.0030517578125,0) [0|199.996948242188] ""  IOT_Gateway

BO_ 115 RatChaCellBattPwrHi_4: 64 BMC
 SG_ RatChaCellBattPwrHi_8_16 : 496|16@1+ (0.0030517578125,0) [0|199.996948242188] ""  IOT_Gateway
 SG_ RatChaCellBattPwrHi_8_15 : 480|16@1+ (0.0030517578125,0) [0|199.996948242188] ""  IOT_Gateway
 SG_ RatChaCellBattPwrHi_8_14 : 464|16@1+ (0.0030517578125,0) [0|199.996948242188] ""  IOT_Gateway
 SG_ RatChaCellBattPwrHi_8_13 : 448|16@1+ (0.0030517578125,0) [0|199.996948242188] ""  IOT_Gateway
 SG_ RatChaCellBattPwrHi_8_12 : 432|16@1+ (0.0030517578125,0) [0|199.996948242188] ""  IOT_Gateway
 SG_ RatChaCellBattPwrHi_8_11 : 416|16@1+ (0.0030517578125,0) [0|199.996948242188] ""  IOT_Gateway
 SG_ RatChaCellBattPwrHi_8_10 : 400|16@1+ (0.0030517578125,0) [0|199.996948242188] ""  IOT_Gateway
 SG_ RatChaCellBattPwrHi_8_9 : 384|16@1+ (0.0030517578125,0) [0|199.996948242188] ""  IOT_Gateway
 SG_ RatChaCellBattPwrHi_8_8 : 368|16@1+ (0.0030517578125,0) [0|199.996948242188] ""  IOT_Gateway
 SG_ RatChaCellBattPwrHi_8_7 : 352|16@1+ (0.0030517578125,0) [0|199.996948242188] ""  IOT_Gateway
 SG_ RatChaCellBattPwrHi_8_6 : 336|16@1+ (0.0030517578125,0) [0|199.996948242188] ""  IOT_Gateway
 SG_ RatChaCellBattPwrHi_8_5 : 320|16@1+ (0.0030517578125,0) [0|199.996948242188] ""  IOT_Gateway
 SG_ RatChaCellBattPwrHi_8_4 : 304|16@1+ (0.0030517578125,0) [0|199.996948242188] ""  IOT_Gateway
 SG_ RatChaCellBattPwrHi_8_3 : 288|16@1+ (0.0030517578125,0) [0|199.996948242188] ""  IOT_Gateway
 SG_ RatChaCellBattPwrHi_8_2 : 272|16@1+ (0.0030517578125,0) [0|199.996948242188] ""  IOT_Gateway
 SG_ RatChaCellBattPwrHi_8_1 : 256|16@1+ (0.0030517578125,0) [0|199.996948242188] ""  IOT_Gateway
 SG_ RatChaCellBattPwrHi_7_16 : 240|16@1+ (0.0030517578125,0) [0|199.996948242188] ""  IOT_Gateway
 SG_ RatChaCellBattPwrHi_7_15 : 224|16@1+ (0.0030517578125,0) [0|199.996948242188] ""  IOT_Gateway
 SG_ RatChaCellBattPwrHi_7_14 : 208|16@1+ (0.0030517578125,0) [0|199.996948242188] ""  IOT_Gateway
 SG_ RatChaCellBattPwrHi_7_13 : 192|16@1+ (0.0030517578125,0) [0|199.996948242188] ""  IOT_Gateway
 SG_ RatChaCellBattPwrHi_7_12 : 176|16@1+ (0.0030517578125,0) [0|199.996948242188] ""  IOT_Gateway
 SG_ RatChaCellBattPwrHi_7_11 : 160|16@1+ (0.0030517578125,0) [0|199.996948242188] ""  IOT_Gateway
 SG_ RatChaCellBattPwrHi_7_10 : 144|16@1+ (0.0030517578125,0) [0|199.996948242188] ""  IOT_Gateway
 SG_ RatChaCellBattPwrHi_7_9 : 128|16@1+ (0.0030517578125,0) [0|199.996948242188] ""  IOT_Gateway
 SG_ RatChaCellBattPwrHi_7_8 : 112|16@1+ (0.0030517578125,0) [0|199.996948242188] ""  IOT_Gateway
 SG_ RatChaCellBattPwrHi_7_7 : 96|16@1+ (0.0030517578125,0) [0|199.996948242188] ""  IOT_Gateway
 SG_ RatChaCellBattPwrHi_7_6 : 80|16@1+ (0.0030517578125,0) [0|199.996948242188] ""  IOT_Gateway
 SG_ RatChaCellBattPwrHi_7_5 : 64|16@1+ (0.0030517578125,0) [0|199.996948242188] ""  IOT_Gateway
 SG_ RatChaCellBattPwrHi_7_4 : 48|16@1+ (0.0030517578125,0) [0|199.996948242188] ""  IOT_Gateway
 SG_ RatChaCellBattPwrHi_7_3 : 32|16@1+ (0.0030517578125,0) [0|199.996948242188] ""  IOT_Gateway
 SG_ RatChaCellBattPwrHi_7_2 : 16|16@1+ (0.0030517578125,0) [0|199.996948242188] ""  IOT_Gateway
 SG_ RatChaCellBattPwrHi_7_1 : 0|16@1+ (0.0030517578125,0) [0|199.996948242188] ""  IOT_Gateway

BO_ 114 RatChaCellBattPwrHi_3: 64 BMC
 SG_ RatChaCellBattPwrHi_6_16 : 496|16@1+ (0.0030517578125,0) [0|199.996948242188] ""  IOT_Gateway
 SG_ RatChaCellBattPwrHi_6_15 : 480|16@1+ (0.0030517578125,0) [0|199.996948242188] ""  IOT_Gateway
 SG_ RatChaCellBattPwrHi_6_14 : 464|16@1+ (0.0030517578125,0) [0|199.996948242188] ""  IOT_Gateway
 SG_ RatChaCellBattPwrHi_6_13 : 448|16@1+ (0.0030517578125,0) [0|199.996948242188] ""  IOT_Gateway
 SG_ RatChaCellBattPwrHi_6_12 : 432|16@1+ (0.0030517578125,0) [0|199.996948242188] ""  IOT_Gateway
 SG_ RatChaCellBattPwrHi_6_11 : 416|16@1+ (0.0030517578125,0) [0|199.996948242188] ""  IOT_Gateway
 SG_ RatChaCellBattPwrHi_6_10 : 400|16@1+ (0.0030517578125,0) [0|199.996948242188] ""  IOT_Gateway
 SG_ RatChaCellBattPwrHi_6_9 : 384|16@1+ (0.0030517578125,0) [0|199.996948242188] ""  IOT_Gateway
 SG_ RatChaCellBattPwrHi_6_8 : 368|16@1+ (0.0030517578125,0) [0|199.996948242188] ""  IOT_Gateway
 SG_ RatChaCellBattPwrHi_6_7 : 352|16@1+ (0.0030517578125,0) [0|199.996948242188] ""  IOT_Gateway
 SG_ RatChaCellBattPwrHi_6_6 : 336|16@1+ (0.0030517578125,0) [0|199.996948242188] ""  IOT_Gateway
 SG_ RatChaCellBattPwrHi_6_5 : 320|16@1+ (0.0030517578125,0) [0|199.996948242188] ""  IOT_Gateway
 SG_ RatChaCellBattPwrHi_6_4 : 304|16@1+ (0.0030517578125,0) [0|199.996948242188] ""  IOT_Gateway
 SG_ RatChaCellBattPwrHi_6_3 : 288|16@1+ (0.0030517578125,0) [0|199.996948242188] ""  IOT_Gateway
 SG_ RatChaCellBattPwrHi_6_2 : 272|16@1+ (0.0030517578125,0) [0|199.996948242188] ""  IOT_Gateway
 SG_ RatChaCellBattPwrHi_6_1 : 256|16@1+ (0.0030517578125,0) [0|199.996948242188] ""  IOT_Gateway
 SG_ RatChaCellBattPwrHi_5_16 : 240|16@1+ (0.0030517578125,0) [0|199.996948242188] ""  IOT_Gateway
 SG_ RatChaCellBattPwrHi_5_15 : 224|16@1+ (0.0030517578125,0) [0|199.996948242188] ""  IOT_Gateway
 SG_ RatChaCellBattPwrHi_5_14 : 208|16@1+ (0.0030517578125,0) [0|199.996948242188] ""  IOT_Gateway
 SG_ RatChaCellBattPwrHi_5_13 : 192|16@1+ (0.0030517578125,0) [0|199.996948242188] ""  IOT_Gateway
 SG_ RatChaCellBattPwrHi_5_12 : 176|16@1+ (0.0030517578125,0) [0|199.996948242188] ""  IOT_Gateway
 SG_ RatChaCellBattPwrHi_5_11 : 160|16@1+ (0.0030517578125,0) [0|199.996948242188] ""  IOT_Gateway
 SG_ RatChaCellBattPwrHi_5_10 : 144|16@1+ (0.0030517578125,0) [0|199.996948242188] ""  IOT_Gateway
 SG_ RatChaCellBattPwrHi_5_9 : 128|16@1+ (0.0030517578125,0) [0|199.996948242188] ""  IOT_Gateway
 SG_ RatChaCellBattPwrHi_5_8 : 112|16@1+ (0.0030517578125,0) [0|199.996948242188] ""  IOT_Gateway
 SG_ RatChaCellBattPwrHi_5_7 : 96|16@1+ (0.0030517578125,0) [0|199.996948242188] ""  IOT_Gateway
 SG_ RatChaCellBattPwrHi_5_6 : 80|16@1+ (0.0030517578125,0) [0|199.996948242188] ""  IOT_Gateway
 SG_ RatChaCellBattPwrHi_5_5 : 64|16@1+ (0.0030517578125,0) [0|199.996948242188] ""  IOT_Gateway
 SG_ RatChaCellBattPwrHi_5_4 : 48|16@1+ (0.0030517578125,0) [0|199.996948242188] ""  IOT_Gateway
 SG_ RatChaCellBattPwrHi_5_3 : 32|16@1+ (0.0030517578125,0) [0|199.996948242188] ""  IOT_Gateway
 SG_ RatChaCellBattPwrHi_5_2 : 16|16@1+ (0.0030517578125,0) [0|199.996948242188] ""  IOT_Gateway
 SG_ RatChaCellBattPwrHi_5_1 : 0|16@1+ (0.0030517578125,0) [0|199.996948242188] ""  IOT_Gateway

BO_ 113 RatChaCellBattPwrHi_2: 64 BMC
 SG_ RatChaCellBattPwrHi_4_16 : 496|16@1+ (0.0030517578125,0) [0|199.996948242188] ""  IOT_Gateway
 SG_ RatChaCellBattPwrHi_4_15 : 480|16@1+ (0.0030517578125,0) [0|199.996948242188] ""  IOT_Gateway
 SG_ RatChaCellBattPwrHi_4_14 : 464|16@1+ (0.0030517578125,0) [0|199.996948242188] ""  IOT_Gateway
 SG_ RatChaCellBattPwrHi_4_13 : 448|16@1+ (0.0030517578125,0) [0|199.996948242188] ""  IOT_Gateway
 SG_ RatChaCellBattPwrHi_4_12 : 432|16@1+ (0.0030517578125,0) [0|199.996948242188] ""  IOT_Gateway
 SG_ RatChaCellBattPwrHi_4_11 : 416|16@1+ (0.0030517578125,0) [0|199.996948242188] ""  IOT_Gateway
 SG_ RatChaCellBattPwrHi_4_10 : 400|16@1+ (0.0030517578125,0) [0|199.996948242188] ""  IOT_Gateway
 SG_ RatChaCellBattPwrHi_4_9 : 384|16@1+ (0.0030517578125,0) [0|199.996948242188] ""  IOT_Gateway
 SG_ RatChaCellBattPwrHi_4_8 : 368|16@1+ (0.0030517578125,0) [0|199.996948242188] ""  IOT_Gateway
 SG_ RatChaCellBattPwrHi_4_7 : 352|16@1+ (0.0030517578125,0) [0|199.996948242188] ""  IOT_Gateway
 SG_ RatChaCellBattPwrHi_4_6 : 336|16@1+ (0.0030517578125,0) [0|199.996948242188] ""  IOT_Gateway
 SG_ RatChaCellBattPwrHi_4_5 : 320|16@1+ (0.0030517578125,0) [0|199.996948242188] ""  IOT_Gateway
 SG_ RatChaCellBattPwrHi_4_4 : 304|16@1+ (0.0030517578125,0) [0|199.996948242188] ""  IOT_Gateway
 SG_ RatChaCellBattPwrHi_4_3 : 288|16@1+ (0.0030517578125,0) [0|199.996948242188] ""  IOT_Gateway
 SG_ RatChaCellBattPwrHi_4_2 : 272|16@1+ (0.0030517578125,0) [0|199.996948242188] ""  IOT_Gateway
 SG_ RatChaCellBattPwrHi_4_1 : 256|16@1+ (0.0030517578125,0) [0|199.996948242188] ""  IOT_Gateway
 SG_ RatChaCellBattPwrHi_3_16 : 240|16@1+ (0.0030517578125,0) [0|199.996948242188] ""  IOT_Gateway
 SG_ RatChaCellBattPwrHi_3_15 : 224|16@1+ (0.0030517578125,0) [0|199.996948242188] ""  IOT_Gateway
 SG_ RatChaCellBattPwrHi_3_14 : 208|16@1+ (0.0030517578125,0) [0|199.996948242188] ""  IOT_Gateway
 SG_ RatChaCellBattPwrHi_3_13 : 192|16@1+ (0.0030517578125,0) [0|199.996948242188] ""  IOT_Gateway
 SG_ RatChaCellBattPwrHi_3_12 : 176|16@1+ (0.0030517578125,0) [0|199.996948242188] ""  IOT_Gateway
 SG_ RatChaCellBattPwrHi_3_11 : 160|16@1+ (0.0030517578125,0) [0|199.996948242188] ""  IOT_Gateway
 SG_ RatChaCellBattPwrHi_3_10 : 144|16@1+ (0.0030517578125,0) [0|199.996948242188] ""  IOT_Gateway
 SG_ RatChaCellBattPwrHi_3_9 : 128|16@1+ (0.0030517578125,0) [0|199.996948242188] ""  IOT_Gateway
 SG_ RatChaCellBattPwrHi_3_8 : 112|16@1+ (0.0030517578125,0) [0|199.996948242188] ""  IOT_Gateway
 SG_ RatChaCellBattPwrHi_3_7 : 96|16@1+ (0.0030517578125,0) [0|199.996948242188] ""  IOT_Gateway
 SG_ RatChaCellBattPwrHi_3_6 : 80|16@1+ (0.0030517578125,0) [0|199.996948242188] ""  IOT_Gateway
 SG_ RatChaCellBattPwrHi_3_5 : 64|16@1+ (0.0030517578125,0) [0|199.996948242188] ""  IOT_Gateway
 SG_ RatChaCellBattPwrHi_3_4 : 48|16@1+ (0.0030517578125,0) [0|199.996948242188] ""  IOT_Gateway
 SG_ RatChaCellBattPwrHi_3_3 : 32|16@1+ (0.0030517578125,0) [0|199.996948242188] ""  IOT_Gateway
 SG_ RatChaCellBattPwrHi_3_2 : 16|16@1+ (0.0030517578125,0) [0|199.996948242188] ""  IOT_Gateway
 SG_ RatChaCellBattPwrHi_3_1 : 0|16@1+ (0.0030517578125,0) [0|199.996948242188] ""  IOT_Gateway

CM_ BO_ 3221225472 "This is a message for not used signals, created by Vector CANdb++ DBC OLE DB Provider.";
CM_ SG_ 130 TAuxBattMonEgyHi_16_1 "Temperature of balancing Circuit";
CM_ SG_ 130 TAuxBattMonEgyHi_15_1 "Temperature of balancing Circuit";
CM_ SG_ 130 TAuxBattMonEgyHi_14_1 "Temperature of balancing Circuit";
CM_ SG_ 130 TAuxBattMonEgyHi_13_1 "Temperature of balancing Circuit";
CM_ SG_ 130 TAuxBattMonEgyHi_12_1 "Temperature of balancing Circuit";
CM_ SG_ 130 TAuxBattMonEgyHi_11_1 "Temperature of balancing Circuit";
CM_ SG_ 130 TAuxBattMonEgyHi_10_1 "Temperature of balancing Circuit";
CM_ SG_ 130 TAuxBattMonEgyHi_9_1 "Temperature of balancing Circuit";
CM_ SG_ 130 TAuxBattMonEgyHi_8_1 "Temperature of balancing Circuit";
CM_ SG_ 130 TAuxBattMonEgyHi_7_1 "Temperature of balancing Circuit";
CM_ SG_ 130 TAuxBattMonEgyHi_6_1 "Temperature of balancing Circuit";
CM_ SG_ 130 TAuxBattMonEgyHi_5_1 "Temperature of balancing Circuit";
CM_ SG_ 130 TAuxBattMonEgyHi_4_1 "Temperature of balancing Circuit";
CM_ SG_ 130 TAuxBattMonEgyHi_3_1 "Temperature of balancing Circuit";
CM_ SG_ 130 TAuxBattMonEgyHi_2_1 "Temperature of balancing Circuit";
CM_ SG_ 130 TAuxBattMonEgyHi_1_1 "Temperature of balancing Circuit";
CM_ SG_ 130 TAuxBattMonPwrHi_16_1 "Temperature of balancing Circuit";
CM_ SG_ 130 TAuxBattMonPwrHi_15_1 "Temperature of balancing Circuit";
CM_ SG_ 130 TAuxBattMonPwrHi_14_1 "Temperature of balancing Circuit";
CM_ SG_ 130 TAuxBattMonPwrHi_13_1 "Temperature of balancing Circuit";
CM_ SG_ 130 TAuxBattMonPwrHi_12_1 "Temperature of balancing Circuit";
CM_ SG_ 130 TAuxBattMonPwrHi_11_1 "Temperature of balancing Circuit";
CM_ SG_ 130 TAuxBattMonPwrHi_10_1 "Temperature of balancing Circuit";
CM_ SG_ 130 TAuxBattMonPwrHi_1_1 "Temperature of balancing Circuit";
CM_ SG_ 111 TCellBattEgyHi_16_6 "High energy battery cell temperatures";
CM_ SG_ 111 TCellBattEgyHi_16_5 "High energy battery cell temperatures";
CM_ SG_ 111 TCellBattEgyHi_16_4 "High energy battery cell temperatures";
CM_ SG_ 111 TCellBattEgyHi_16_3 "High energy battery cell temperatures";
CM_ SG_ 111 TCellBattEgyHi_16_2 "High energy battery cell temperatures";
CM_ SG_ 111 TCellBattEgyHi_16_1 "High energy battery cell temperatures";
CM_ SG_ 110 TCellBattEgyHi_15_6 "High energy battery cell temperatures";
CM_ SG_ 110 TCellBattEgyHi_15_5 "High energy battery cell temperatures";
CM_ SG_ 110 TCellBattEgyHi_15_4 "High energy battery cell temperatures";
CM_ SG_ 110 TCellBattEgyHi_15_3 "High energy battery cell temperatures";
CM_ SG_ 110 TCellBattEgyHi_15_2 "High energy battery cell temperatures";
CM_ SG_ 110 TCellBattEgyHi_15_1 "High energy battery cell temperatures";
CM_ SG_ 109 TCellBattEgyHi_14_6 "High energy battery cell temperatures";
CM_ SG_ 109 TCellBattEgyHi_14_5 "High energy battery cell temperatures";
CM_ SG_ 109 TCellBattEgyHi_14_4 "High energy battery cell temperatures";
CM_ SG_ 109 TCellBattEgyHi_14_3 "High energy battery cell temperatures";
CM_ SG_ 109 TCellBattEgyHi_14_2 "High energy battery cell temperatures";
CM_ SG_ 109 TCellBattEgyHi_14_1 "High energy battery cell temperatures";
CM_ SG_ 108 TCellBattEgyHi_13_6 "High energy battery cell temperatures";
CM_ SG_ 108 TCellBattEgyHi_13_5 "High energy battery cell temperatures";
CM_ SG_ 108 TCellBattEgyHi_13_4 "High energy battery cell temperatures";
CM_ SG_ 108 TCellBattEgyHi_13_3 "High energy battery cell temperatures";
CM_ SG_ 108 TCellBattEgyHi_13_2 "High energy battery cell temperatures";
CM_ SG_ 108 TCellBattEgyHi_13_1 "High energy battery cell temperatures";
CM_ SG_ 95 TCellBattPwrHi_16_6 "High power battery cell temperatures";
CM_ SG_ 95 TCellBattPwrHi_16_5 "High power battery cell temperatures";
CM_ SG_ 95 TCellBattPwrHi_16_4 "High power battery cell temperatures";
CM_ SG_ 95 TCellBattPwrHi_16_3 "High power battery cell temperatures";
CM_ SG_ 95 TCellBattPwrHi_16_2 "High power battery cell temperatures";
CM_ SG_ 95 TCellBattPwrHi_16_1 "High power battery cell temperaturesHigh power battery cell temperatures";
CM_ SG_ 94 TCellBattPwrHi_15_6 "High power battery cell temperatures";
CM_ SG_ 94 TCellBattPwrHi_15_5 "High power battery cell temperatures";
CM_ SG_ 94 TCellBattPwrHi_15_4 "High power battery cell temperatures";
CM_ SG_ 94 TCellBattPwrHi_15_3 "High power battery cell temperatures";
CM_ SG_ 94 TCellBattPwrHi_15_2 "High power battery cell temperatures";
CM_ SG_ 93 TCellBattPwrHi_14_6 "High power battery cell temperatures";
CM_ SG_ 93 TCellBattPwrHi_14_5 "High power battery cell temperatures";
CM_ SG_ 93 TCellBattPwrHi_14_4 "High power battery cell temperatures";
CM_ SG_ 93 TCellBattPwrHi_14_3 "High power battery cell temperatures";
CM_ SG_ 93 TCellBattPwrHi_14_2 "High power battery cell temperatures";
CM_ SG_ 93 TCellBattPwrHi_14_1 "High power battery cell temperatures";
CM_ SG_ 92 TCellBattPwrHi_13_6 "High power battery cell temperatures";
CM_ SG_ 92 TCellBattPwrHi_13_5 "High power battery cell temperatures";
CM_ SG_ 92 TCellBattPwrHi_13_4 "High power battery cell temperatures";
CM_ SG_ 92 TCellBattPwrHi_13_3 "High power battery cell temperatures";
CM_ SG_ 92 TCellBattPwrHi_13_2 "High power battery cell temperatures";
CM_ SG_ 92 TCellBattPwrHi_13_1 "High power battery cell temperatures";
CM_ SG_ 1654 VERSION_MINOR_8 "MSU SW Version";
CM_ SG_ 1654 VERSION_MAJOR_8 "MSU SW Version";
CM_ SG_ 1638 VERSION_MINOR_7 "MSU SW Version";
CM_ SG_ 1638 VERSION_MAJOR_7 "MSU SW Version";
CM_ SG_ 1606 VERSION_MINOR_5 "MSU SW Version";
CM_ SG_ 1606 VERSION_MAJOR_5 "MSU SW Version";
CM_ SG_ 1590 VERSION_MINOR_4 "MSU SW Version";
CM_ SG_ 1590 VERSION_MAJOR_4 "MSU SW Version";
CM_ SG_ 1622 VERSION_MINOR_6 "MSU SW Version";
CM_ SG_ 1622 VERSION_MAJOR_6 "MSU SW Version";
CM_ SG_ 1574 VERSION_MINOR_3 "MSU SW Version";
CM_ SG_ 1574 VERSION_MAJOR_3 "MSU SW Version";
CM_ SG_ 1558 VERSION_MINOR_2 "MSU SW Version";
CM_ SG_ 1558 VERSION_MAJOR_2 "MSU SW Version";
CM_ SG_ 1542 VERSION_MINOR_1 "MSU SW Version";
CM_ SG_ 1542 VERSION_MAJOR_1 "MSU SW Version";
CM_ SG_ 1653 Filter_Pressure_Diff_4_8 "Battery pack pressure gradient filter 4";
CM_ SG_ 1653 Filter_Pressure_Diff_3_8 "Battery pack pressure gradient filter 3";
CM_ SG_ 1653 Filter_Pressure_Diff_2_8 "Battery pack pressure gradient filter 2";
CM_ SG_ 1653 Filter_Pressure_Diff_1_8 "Battery pack pressure gradient filter 1";
CM_ SG_ 1653 Filter_Pressure_Abs_8 "Battery pack absolute pressure level trigger";
CM_ SG_ 1653 Filter_H2C_Abs_8 "Battery pack hydrogen concentration trigger";
CM_ SG_ 1653 ADC_VBAT_8 "MSU Supply voltage";
CM_ SG_ 1653 ADC_NTC2_8 "Air temperature inside the battery pack";
CM_ SG_ 1637 Filter_Pressure_Diff_4_7 "Battery pack pressure gradient filter 4";
CM_ SG_ 1637 Filter_Pressure_Diff_3_7 "Battery pack pressure gradient filter 3";
CM_ SG_ 1637 Filter_Pressure_Diff_2_7 "Battery pack pressure gradient filter 2";
CM_ SG_ 1637 Filter_Pressure_Diff_1_7 "Battery pack pressure gradient filter 1";
CM_ SG_ 1637 Filter_Pressure_Abs_7 "Battery pack absolute pressure level trigger";
CM_ SG_ 1637 Filter_H2C_Abs_7 "Battery pack hydrogen concentration trigger";
CM_ SG_ 1637 ADC_VBAT_7 "MSU Supply voltage";
CM_ SG_ 1637 ADC_NTC2_7 "Air temperature inside the battery pack";
CM_ SG_ 1621 Filter_Pressure_Diff_4_6 "Battery pack pressure gradient filter 4";
CM_ SG_ 1621 Filter_Pressure_Diff_3_6 "Battery pack pressure gradient filter 3";
CM_ SG_ 1621 Filter_Pressure_Diff_2_6 "Battery pack pressure gradient filter 2";
CM_ SG_ 1621 Filter_Pressure_Diff_1_6 "Battery pack pressure gradient filter 1";
CM_ SG_ 1621 Filter_Pressure_Abs_6 "Battery pack absolute pressure level trigger";
CM_ SG_ 1621 Filter_H2C_Abs_6 "Battery pack hydrogen concentration trigger";
CM_ SG_ 1621 ADC_VBAT_6 "MSU Supply voltage";
CM_ SG_ 1621 ADC_NTC2_6 "Air temperature inside the battery pack";
CM_ SG_ 1605 Filter_Pressure_Diff_4_5 "Battery pack pressure gradient filter 4";
CM_ SG_ 1605 Filter_Pressure_Diff_3_5 "Battery pack pressure gradient filter 3";
CM_ SG_ 1605 Filter_Pressure_Diff_2_5 "Battery pack pressure gradient filter 2";
CM_ SG_ 1605 Filter_Pressure_Diff_1_5 "Battery pack pressure gradient filter 1";
CM_ SG_ 1605 Filter_Pressure_Abs_5 "Battery pack absolute pressure level trigger";
CM_ SG_ 1605 Filter_H2C_Abs_5 "Battery pack hydrogen concentration trigger";
CM_ SG_ 1605 ADC_VBAT_5 "MSU Supply voltage";
CM_ SG_ 1605 ADC_NTC2_5 "Air temperature inside the battery pack";
CM_ SG_ 1589 Filter_Pressure_Diff_4_4 "Battery pack pressure gradient filter 4";
CM_ SG_ 1589 Filter_Pressure_Diff_3_4 "Battery pack pressure gradient filter 3";
CM_ SG_ 1589 Filter_Pressure_Diff_2_4 "Battery pack pressure gradient filter 2";
CM_ SG_ 1589 Filter_Pressure_Diff_1_4 "Battery pack pressure gradient filter 1";
CM_ SG_ 1589 Filter_Pressure_Abs_4 "Battery pack absolute pressure level trigger";
CM_ SG_ 1589 Filter_H2C_Abs_4 "Battery pack hydrogen concentration trigger";
CM_ SG_ 1589 ADC_VBAT_4 "MSU Supply voltage";
CM_ SG_ 1589 ADC_NTC2_4 "Air temperature inside the battery pack";
CM_ SG_ 1573 Filter_Pressure_Diff_4_3 "Battery pack pressure gradient filter 4";
CM_ SG_ 1573 Filter_Pressure_Diff_3_3 "Battery pack pressure gradient filter 3";
CM_ SG_ 1573 Filter_Pressure_Diff_2_3 "Battery pack pressure gradient filter 2";
CM_ SG_ 1573 Filter_Pressure_Diff_1_3 "Battery pack pressure gradient filter 1";
CM_ SG_ 1573 Filter_Pressure_Abs_3 "Battery pack absolute pressure level trigger";
CM_ SG_ 1573 Filter_H2C_Abs_3 "Battery pack hydrogen concentration trigger";
CM_ SG_ 1573 ADC_VBAT_3 "MSU Supply voltage";
CM_ SG_ 1573 ADC_NTC2_3 "Air temperature inside the battery pack";
CM_ SG_ 1557 Filter_Pressure_Diff_4_2 "Battery pack pressure gradient filter 4";
CM_ SG_ 1557 Filter_Pressure_Diff_3_2 "Battery pack pressure gradient filter 3";
CM_ SG_ 1557 Filter_Pressure_Diff_2_2 "Battery pack pressure gradient filter 2";
CM_ SG_ 1557 Filter_Pressure_Diff_1_2 "Battery pack pressure gradient filter 1";
CM_ SG_ 1557 Filter_Pressure_Abs_2 "Battery pack absolute pressure level trigger";
CM_ SG_ 1557 Filter_H2C_Abs_2 "Battery pack hydrogen concentration trigger";
CM_ SG_ 1557 ADC_VBAT_2 "MSU Supply voltage";
CM_ SG_ 1557 ADC_NTC2_2 "Air temperature inside the battery pack";
CM_ SG_ 1541 ADC_VBAT_1 "MSU Supply voltage";
CM_ SG_ 1541 Filter_H2C_Abs_1 "Battery pack hydrogen concentration trigger";
CM_ SG_ 1541 Filter_Pressure_Abs_1 "Battery pack absolute pressure level trigger";
CM_ SG_ 1541 Filter_Pressure_Diff_4_1 "Battery pack pressure gradient filter 4";
CM_ SG_ 1541 Filter_Pressure_Diff_3_1 "Battery pack pressure gradient filter 3";
CM_ SG_ 1541 Filter_Pressure_Diff_2_1 "Battery pack pressure gradient filter 2";
CM_ SG_ 1541 Filter_Pressure_Diff_1_1 "Battery pack pressure gradient filter 1";
CM_ SG_ 1541 ADC_NTC2_1 "Air temperature inside the battery pack";
CM_ SG_ 1652 KP466_Status_8 "Battery pack pressure sensor status";
CM_ SG_ 1652 KP466_Pressure_8 "Pressure inside the battery pack";
CM_ SG_ 1636 KP466_Status_7 "Battery pack pressure sensor status";
CM_ SG_ 1636 KP466_Pressure_7 "Pressure inside the battery pack";
CM_ SG_ 1620 KP466_Status_6 "Battery pack pressure sensor status";
CM_ SG_ 1620 KP466_Pressure_6 "Pressure inside the battery pack";
CM_ SG_ 1604 KP466_Status_5 "Battery pack pressure sensor status";
CM_ SG_ 1604 KP466_Pressure_5 "Pressure inside the battery pack";
CM_ SG_ 1588 KP466_Status_4 "Battery pack pressure sensor status";
CM_ SG_ 1588 KP466_Pressure_4 "Pressure inside the battery pack";
CM_ SG_ 1572 KP466_Status_3 "Battery pack pressure sensor status";
CM_ SG_ 1572 KP466_Pressure_3 "Pressure inside the battery pack";
CM_ SG_ 1556 KP466_Status_2 "Battery pack pressure sensor status";
CM_ SG_ 1556 KP466_Pressure_2 "Pressure inside the battery pack";
CM_ SG_ 1540 KP466_Pressure_1 "Pressure inside the battery pack";
CM_ SG_ 1540 KP466_Status_1 "Battery pack pressure sensor status";
CM_ SG_ 1650 SHT_Status_8 "Battery pack humidity sensor status";
CM_ SG_ 1650 SHT_Humidity_8 "Relative humidity inside the battery pack";
CM_ SG_ 1634 SHT_Status_7 "Battery pack humidity sensor status";
CM_ SG_ 1634 SHT_Humidity_7 "Relative humidity inside the battery pack";
CM_ SG_ 1618 SHT_Status_6 "Battery pack humidity sensor status";
CM_ SG_ 1618 SHT_Humidity_6 "Relative humidity inside the battery pack";
CM_ SG_ 1602 SHT_Status_5 "Battery pack humidity sensor status";
CM_ SG_ 1602 SHT_Humidity_5 "Relative humidity inside the battery pack";
CM_ SG_ 1586 SHT_Status_4 "Battery pack humidity sensor status";
CM_ SG_ 1586 SHT_Humidity_4 "Relative humidity inside the battery pack";
CM_ SG_ 1570 SHT_Status_3 "Battery pack humidity sensor status";
CM_ SG_ 1570 SHT_Humidity_3 "Relative humidity inside the battery pack";
CM_ SG_ 1554 SHT_Status_2 "Battery pack humidity sensor status";
CM_ SG_ 1554 SHT_Humidity_2 "Relative humidity inside the battery pack";
CM_ SG_ 1538 SHT_Status_1 "Battery pack humidity sensor status";
CM_ SG_ 1538 SHT_Humidity_1 "Relative humidity inside the battery pack";
CM_ SG_ 1649 SHT_Temperature_8 "Humidity sensor temperature inside the battery pack";
CM_ SG_ 1633 SHT_Temperature_7 "Humidity sensor temperature inside the battery pack";
CM_ SG_ 1617 SHT_Temperature_6 "Humidity sensor temperature inside the battery pack";
CM_ SG_ 1601 SHT_Temperature_5 "Humidity sensor temperature inside the battery pack";
CM_ SG_ 1585 SHT_Temperature_4 "Humidity sensor temperature inside the battery pack";
CM_ SG_ 1569 SHT_Temperature_3 "Humidity sensor temperature inside the battery pack";
CM_ SG_ 1553 SHT_Temperature_2 "Humidity sensor temperature inside the battery pack";
CM_ SG_ 1537 SHT_Temperature_1 "Humidity sensor temperature inside the battery pack";
CM_ SG_ 1648 H2CS_H2C_8 "H2 Concentration inside the battery pack
";
CM_ SG_ 1632 H2CS_H2C_7 "H2 Concentration inside the battery pack
";
CM_ SG_ 1616 H2CS_H2C_6 "H2 Concentration inside the battery pack
";
CM_ SG_ 1600 H2CS_H2C_5 "H2 Concentration inside the battery pack
";
CM_ SG_ 1584 H2CS_H2C_4 "H2 Concentration inside the battery pack
";
CM_ SG_ 1568 H2CS_H2C_3 "H2 Concentration inside the battery pack
";
CM_ SG_ 1552 H2CS_H2C_2 "H2 Concentration inside the battery pack
";
CM_ SG_ 1536 H2CS_H2C_1 "H2 Concentration inside the battery pack
";
CM_ SG_ 127 RatChaCellBattEgyHi_16_16 "High energy battery state of charge on cell level";
CM_ SG_ 127 RatChaCellBattEgyHi_16_15 "High energy battery state of charge on cell level";
CM_ SG_ 127 RatChaCellBattEgyHi_16_14 "High energy battery state of charge on cell level";
CM_ SG_ 127 RatChaCellBattEgyHi_16_13 "High energy battery state of charge on cell level";
CM_ SG_ 127 RatChaCellBattEgyHi_16_12 "High energy battery state of charge on cell level";
CM_ SG_ 127 RatChaCellBattEgyHi_16_11 "High energy battery state of charge on cell level";
CM_ SG_ 127 RatChaCellBattEgyHi_16_10 "High energy battery state of charge on cell level";
CM_ SG_ 127 RatChaCellBattEgyHi_16_9 "High energy battery state of charge on cell level";
CM_ SG_ 127 RatChaCellBattEgyHi_16_8 "High energy battery state of charge on cell level";
CM_ SG_ 127 RatChaCellBattEgyHi_16_7 "High energy battery state of charge on cell level";
CM_ SG_ 127 RatChaCellBattEgyHi_16_6 "High energy battery state of charge on cell level";
CM_ SG_ 127 RatChaCellBattEgyHi_16_5 "High energy battery state of charge on cell level";
CM_ SG_ 127 RatChaCellBattEgyHi_16_4 "High energy battery state of charge on cell level";
CM_ SG_ 127 RatChaCellBattEgyHi_16_3 "High energy battery state of charge on cell level";
CM_ SG_ 127 RatChaCellBattEgyHi_16_2 "High energy battery state of charge on cell level";
CM_ SG_ 127 RatChaCellBattEgyHi_16_1 "High energy battery state of charge on cell level";
CM_ SG_ 127 RatChaCellBattEgyHi_15_16 "High energy battery state of charge on cell level";
CM_ SG_ 127 RatChaCellBattEgyHi_15_15 "High energy battery state of charge on cell level";
CM_ SG_ 127 RatChaCellBattEgyHi_15_14 "High energy battery state of charge on cell level";
CM_ SG_ 127 RatChaCellBattEgyHi_15_13 "High energy battery state of charge on cell level";
CM_ SG_ 127 RatChaCellBattEgyHi_15_12 "High energy battery state of charge on cell level";
CM_ SG_ 127 RatChaCellBattEgyHi_15_11 "High energy battery state of charge on cell level";
CM_ SG_ 127 RatChaCellBattEgyHi_15_10 "High energy battery state of charge on cell level";
CM_ SG_ 127 RatChaCellBattEgyHi_15_9 "High energy battery state of charge on cell level";
CM_ SG_ 127 RatChaCellBattEgyHi_15_8 "High energy battery state of charge on cell level";
CM_ SG_ 127 RatChaCellBattEgyHi_15_7 "High energy battery state of charge on cell level";
CM_ SG_ 127 RatChaCellBattEgyHi_15_6 "High energy battery state of charge on cell level";
CM_ SG_ 127 RatChaCellBattEgyHi_15_5 "High energy battery state of charge on cell level";
CM_ SG_ 127 RatChaCellBattEgyHi_15_4 "High energy battery state of charge on cell level";
CM_ SG_ 127 RatChaCellBattEgyHi_15_3 "High energy battery state of charge on cell level";
CM_ SG_ 127 RatChaCellBattEgyHi_15_2 "High energy battery state of charge on cell level";
CM_ SG_ 127 RatChaCellBattEgyHi_15_1 "High energy battery state of charge on cell level";
CM_ SG_ 126 RatChaCellBattEgyHi_14_16 "High energy battery state of charge on cell level";
CM_ SG_ 126 RatChaCellBattEgyHi_14_15 "High energy battery state of charge on cell level";
CM_ SG_ 126 RatChaCellBattEgyHi_14_14 "High energy battery state of charge on cell level";
CM_ SG_ 126 RatChaCellBattEgyHi_14_13 "High energy battery state of charge on cell level";
CM_ SG_ 126 RatChaCellBattEgyHi_14_12 "High energy battery state of charge on cell level";
CM_ SG_ 126 RatChaCellBattEgyHi_14_11 "High energy battery state of charge on cell level";
CM_ SG_ 126 RatChaCellBattEgyHi_14_10 "High energy battery state of charge on cell level";
CM_ SG_ 126 RatChaCellBattEgyHi_14_9 "High energy battery state of charge on cell level";
CM_ SG_ 126 RatChaCellBattEgyHi_14_8 "High energy battery state of charge on cell level";
CM_ SG_ 126 RatChaCellBattEgyHi_14_7 "High energy battery state of charge on cell level";
CM_ SG_ 126 RatChaCellBattEgyHi_14_6 "High energy battery state of charge on cell level";
CM_ SG_ 126 RatChaCellBattEgyHi_14_5 "High energy battery state of charge on cell level";
CM_ SG_ 126 RatChaCellBattEgyHi_14_4 "High energy battery state of charge on cell level";
CM_ SG_ 126 RatChaCellBattEgyHi_14_3 "High energy battery state of charge on cell level";
CM_ SG_ 126 RatChaCellBattEgyHi_14_2 "High energy battery state of charge on cell level";
CM_ SG_ 126 RatChaCellBattEgyHi_14_1 "High energy battery state of charge on cell level";
CM_ SG_ 126 RatChaCellBattEgyHi_13_16 "High energy battery state of charge on cell level";
CM_ SG_ 126 RatChaCellBattEgyHi_13_15 "High energy battery state of charge on cell level";
CM_ SG_ 126 RatChaCellBattEgyHi_13_14 "High energy battery state of charge on cell level";
CM_ SG_ 126 RatChaCellBattEgyHi_13_13 "High energy battery state of charge on cell level";
CM_ SG_ 126 RatChaCellBattEgyHi_13_12 "High energy battery state of charge on cell level";
CM_ SG_ 126 RatChaCellBattEgyHi_13_11 "High energy battery state of charge on cell level";
CM_ SG_ 126 RatChaCellBattEgyHi_13_10 "High energy battery state of charge on cell level";
CM_ SG_ 126 RatChaCellBattEgyHi_13_9 "High energy battery state of charge on cell level";
CM_ SG_ 126 RatChaCellBattEgyHi_13_8 "High energy battery state of charge on cell level";
CM_ SG_ 126 RatChaCellBattEgyHi_13_7 "High energy battery state of charge on cell level";
CM_ SG_ 126 RatChaCellBattEgyHi_13_6 "High energy battery state of charge on cell level";
CM_ SG_ 126 RatChaCellBattEgyHi_13_5 "High energy battery state of charge on cell level";
CM_ SG_ 126 RatChaCellBattEgyHi_13_4 "High energy battery state of charge on cell level";
CM_ SG_ 126 RatChaCellBattEgyHi_13_3 "High energy battery state of charge on cell level";
CM_ SG_ 126 RatChaCellBattEgyHi_13_2 "High energy battery state of charge on cell level";
CM_ SG_ 126 RatChaCellBattEgyHi_13_1 "High energy battery state of charge on cell level";
CM_ SG_ 125 RatChaCellBattEgyHi_12_16 "High energy battery state of charge on cell level";
CM_ SG_ 125 RatChaCellBattEgyHi_12_15 "High energy battery state of charge on cell level";
CM_ SG_ 125 RatChaCellBattEgyHi_12_14 "High energy battery state of charge on cell level";
CM_ SG_ 125 RatChaCellBattEgyHi_12_13 "High energy battery state of charge on cell level";
CM_ SG_ 125 RatChaCellBattEgyHi_12_12 "High energy battery state of charge on cell level";
CM_ SG_ 125 RatChaCellBattEgyHi_12_11 "High energy battery state of charge on cell level";
CM_ SG_ 125 RatChaCellBattEgyHi_12_10 "High energy battery state of charge on cell level";
CM_ SG_ 125 RatChaCellBattEgyHi_12_9 "High energy battery state of charge on cell level";
CM_ SG_ 125 RatChaCellBattEgyHi_12_8 "High energy battery state of charge on cell level";
CM_ SG_ 125 RatChaCellBattEgyHi_12_7 "High energy battery state of charge on cell level";
CM_ SG_ 125 RatChaCellBattEgyHi_12_6 "High energy battery state of charge on cell level";
CM_ SG_ 125 RatChaCellBattEgyHi_12_5 "High energy battery state of charge on cell level";
CM_ SG_ 125 RatChaCellBattEgyHi_12_4 "High energy battery state of charge on cell level";
CM_ SG_ 125 RatChaCellBattEgyHi_12_3 "High energy battery state of charge on cell level";
CM_ SG_ 125 RatChaCellBattEgyHi_12_2 "High energy battery state of charge on cell level";
CM_ SG_ 125 RatChaCellBattEgyHi_12_1 "High energy battery state of charge on cell level";
CM_ SG_ 125 RatChaCellBattEgyHi_11_16 "High energy battery state of charge on cell level";
CM_ SG_ 125 RatChaCellBattEgyHi_11_15 "High energy battery state of charge on cell level";
CM_ SG_ 125 RatChaCellBattEgyHi_11_14 "High energy battery state of charge on cell level";
CM_ SG_ 125 RatChaCellBattEgyHi_11_13 "High energy battery state of charge on cell level";
CM_ SG_ 125 RatChaCellBattEgyHi_11_12 "High energy battery state of charge on cell level";
CM_ SG_ 125 RatChaCellBattEgyHi_11_11 "High energy battery state of charge on cell level";
CM_ SG_ 125 RatChaCellBattEgyHi_11_10 "High energy battery state of charge on cell level";
CM_ SG_ 125 RatChaCellBattEgyHi_11_9 "High energy battery state of charge on cell level";
CM_ SG_ 125 RatChaCellBattEgyHi_11_8 "High energy battery state of charge on cell level";
CM_ SG_ 125 RatChaCellBattEgyHi_11_7 "High energy battery state of charge on cell level";
CM_ SG_ 125 RatChaCellBattEgyHi_11_6 "High energy battery state of charge on cell level";
CM_ SG_ 125 RatChaCellBattEgyHi_11_5 "High energy battery state of charge on cell level";
CM_ SG_ 125 RatChaCellBattEgyHi_11_4 "High energy battery state of charge on cell level";
CM_ SG_ 125 RatChaCellBattEgyHi_11_3 "High energy battery state of charge on cell level";
CM_ SG_ 125 RatChaCellBattEgyHi_11_2 "High energy battery state of charge on cell level";
CM_ SG_ 125 RatChaCellBattEgyHi_11_1 "High energy battery state of charge on cell level";
CM_ SG_ 124 RatChaCellBattEgyHi_10_16 "High energy battery state of charge on cell level";
CM_ SG_ 124 RatChaCellBattEgyHi_10_15 "High energy battery state of charge on cell level";
CM_ SG_ 124 RatChaCellBattEgyHi_10_14 "High energy battery state of charge on cell level";
CM_ SG_ 124 RatChaCellBattEgyHi_10_13 "High energy battery state of charge on cell level";
CM_ SG_ 124 RatChaCellBattEgyHi_10_12 "High energy battery state of charge on cell level";
CM_ SG_ 124 RatChaCellBattEgyHi_10_11 "High energy battery state of charge on cell level";
CM_ SG_ 124 RatChaCellBattEgyHi_10_10 "High energy battery state of charge on cell level";
CM_ SG_ 124 RatChaCellBattEgyHi_10_9 "High energy battery state of charge on cell level";
CM_ SG_ 124 RatChaCellBattEgyHi_10_8 "High energy battery state of charge on cell level";
CM_ SG_ 124 RatChaCellBattEgyHi_10_7 "High energy battery state of charge on cell level";
CM_ SG_ 124 RatChaCellBattEgyHi_10_6 "High energy battery state of charge on cell level";
CM_ SG_ 124 RatChaCellBattEgyHi_10_5 "High energy battery state of charge on cell level";
CM_ SG_ 124 RatChaCellBattEgyHi_10_4 "High energy battery state of charge on cell level";
CM_ SG_ 124 RatChaCellBattEgyHi_10_3 "High energy battery state of charge on cell level";
CM_ SG_ 124 RatChaCellBattEgyHi_10_2 "High energy battery state of charge on cell level";
CM_ SG_ 124 RatChaCellBattEgyHi_10_1 "High energy battery state of charge on cell level";
CM_ SG_ 124 RatChaCellBattEgyHi_9_16 "High energy battery state of charge on cell level";
CM_ SG_ 124 RatChaCellBattEgyHi_9_15 "High energy battery state of charge on cell level";
CM_ SG_ 124 RatChaCellBattEgyHi_9_14 "High energy battery state of charge on cell level";
CM_ SG_ 124 RatChaCellBattEgyHi_9_13 "High energy battery state of charge on cell level";
CM_ SG_ 124 RatChaCellBattEgyHi_9_12 "High energy battery state of charge on cell level";
CM_ SG_ 124 RatChaCellBattEgyHi_9_11 "High energy battery state of charge on cell level";
CM_ SG_ 124 RatChaCellBattEgyHi_9_10 "High energy battery state of charge on cell level";
CM_ SG_ 124 RatChaCellBattEgyHi_9_9 "High energy battery state of charge on cell level";
CM_ SG_ 124 RatChaCellBattEgyHi_9_8 "High energy battery state of charge on cell level";
CM_ SG_ 124 RatChaCellBattEgyHi_9_7 "High energy battery state of charge on cell level";
CM_ SG_ 124 RatChaCellBattEgyHi_9_6 "High energy battery state of charge on cell level";
CM_ SG_ 124 RatChaCellBattEgyHi_9_5 "High energy battery state of charge on cell level";
CM_ SG_ 124 RatChaCellBattEgyHi_9_4 "High energy battery state of charge on cell level";
CM_ SG_ 124 RatChaCellBattEgyHi_9_3 "High energy battery state of charge on cell level";
CM_ SG_ 124 RatChaCellBattEgyHi_9_2 "High energy battery state of charge on cell level";
CM_ SG_ 124 RatChaCellBattEgyHi_9_1 "High energy battery state of charge on cell level";
CM_ SG_ 123 RatChaCellBattEgyHi_8_16 "High energy battery state of charge on cell level";
CM_ SG_ 123 RatChaCellBattEgyHi_8_15 "High energy battery state of charge on cell level";
CM_ SG_ 123 RatChaCellBattEgyHi_8_14 "High energy battery state of charge on cell level";
CM_ SG_ 123 RatChaCellBattEgyHi_8_13 "High energy battery state of charge on cell level";
CM_ SG_ 123 RatChaCellBattEgyHi_8_12 "High energy battery state of charge on cell level";
CM_ SG_ 123 RatChaCellBattEgyHi_8_11 "High energy battery state of charge on cell level";
CM_ SG_ 123 RatChaCellBattEgyHi_8_10 "High energy battery state of charge on cell level";
CM_ SG_ 123 RatChaCellBattEgyHi_8_9 "High energy battery state of charge on cell level";
CM_ SG_ 123 RatChaCellBattEgyHi_8_8 "High energy battery state of charge on cell level";
CM_ SG_ 123 RatChaCellBattEgyHi_8_7 "High energy battery state of charge on cell level";
CM_ SG_ 123 RatChaCellBattEgyHi_8_6 "High energy battery state of charge on cell level";
CM_ SG_ 123 RatChaCellBattEgyHi_8_5 "High energy battery state of charge on cell level";
CM_ SG_ 123 RatChaCellBattEgyHi_8_4 "High energy battery state of charge on cell level";
CM_ SG_ 123 RatChaCellBattEgyHi_8_3 "High energy battery state of charge on cell level";
CM_ SG_ 123 RatChaCellBattEgyHi_8_2 "High energy battery state of charge on cell level";
CM_ SG_ 123 RatChaCellBattEgyHi_8_1 "High energy battery state of charge on cell level";
CM_ SG_ 123 RatChaCellBattEgyHi_7_16 "High energy battery state of charge on cell level";
CM_ SG_ 123 RatChaCellBattEgyHi_7_15 "High energy battery state of charge on cell level";
CM_ SG_ 123 RatChaCellBattEgyHi_7_14 "High energy battery state of charge on cell level";
CM_ SG_ 123 RatChaCellBattEgyHi_7_13 "High energy battery state of charge on cell level";
CM_ SG_ 123 RatChaCellBattEgyHi_7_12 "High energy battery state of charge on cell level";
CM_ SG_ 123 RatChaCellBattEgyHi_7_11 "High energy battery state of charge on cell level";
CM_ SG_ 123 RatChaCellBattEgyHi_7_10 "High energy battery state of charge on cell level";
CM_ SG_ 123 RatChaCellBattEgyHi_7_9 "High energy battery state of charge on cell level";
CM_ SG_ 123 RatChaCellBattEgyHi_7_8 "High energy battery state of charge on cell level";
CM_ SG_ 123 RatChaCellBattEgyHi_7_7 "High energy battery state of charge on cell level";
CM_ SG_ 123 RatChaCellBattEgyHi_7_6 "High energy battery state of charge on cell level";
CM_ SG_ 123 RatChaCellBattEgyHi_7_5 "High energy battery state of charge on cell level";
CM_ SG_ 123 RatChaCellBattEgyHi_7_4 "High energy battery state of charge on cell level";
CM_ SG_ 123 RatChaCellBattEgyHi_7_3 "High energy battery state of charge on cell level";
CM_ SG_ 123 RatChaCellBattEgyHi_7_2 "High energy battery state of charge on cell level";
CM_ SG_ 123 RatChaCellBattEgyHi_7_1 "High energy battery state of charge on cell level";
CM_ SG_ 122 RatChaCellBattEgyHi_6_16 "High energy battery state of charge on cell level";
CM_ SG_ 122 RatChaCellBattEgyHi_6_15 "High energy battery state of charge on cell level";
CM_ SG_ 122 RatChaCellBattEgyHi_6_14 "High energy battery state of charge on cell level";
CM_ SG_ 122 RatChaCellBattEgyHi_6_13 "High energy battery state of charge on cell level";
CM_ SG_ 122 RatChaCellBattEgyHi_6_12 "High energy battery state of charge on cell level";
CM_ SG_ 122 RatChaCellBattEgyHi_6_11 "High energy battery state of charge on cell level";
CM_ SG_ 122 RatChaCellBattEgyHi_6_10 "High energy battery state of charge on cell level";
CM_ SG_ 122 RatChaCellBattEgyHi_6_9 "High energy battery state of charge on cell level";
CM_ SG_ 122 RatChaCellBattEgyHi_6_8 "High energy battery state of charge on cell level";
CM_ SG_ 122 RatChaCellBattEgyHi_6_7 "High energy battery state of charge on cell level";
CM_ SG_ 122 RatChaCellBattEgyHi_6_6 "High energy battery state of charge on cell level";
CM_ SG_ 122 RatChaCellBattEgyHi_6_5 "High energy battery state of charge on cell level";
CM_ SG_ 122 RatChaCellBattEgyHi_6_4 "High energy battery state of charge on cell level";
CM_ SG_ 122 RatChaCellBattEgyHi_6_3 "High energy battery state of charge on cell level";
CM_ SG_ 122 RatChaCellBattEgyHi_6_2 "High energy battery state of charge on cell level";
CM_ SG_ 122 RatChaCellBattEgyHi_6_1 "High energy battery state of charge on cell level";
CM_ SG_ 122 RatChaCellBattEgyHi_5_16 "High energy battery state of charge on cell level";
CM_ SG_ 122 RatChaCellBattEgyHi_5_15 "High energy battery state of charge on cell level";
CM_ SG_ 122 RatChaCellBattEgyHi_5_14 "High energy battery state of charge on cell level";
CM_ SG_ 122 RatChaCellBattEgyHi_5_13 "High energy battery state of charge on cell level";
CM_ SG_ 122 RatChaCellBattEgyHi_5_12 "High energy battery state of charge on cell level";
CM_ SG_ 122 RatChaCellBattEgyHi_5_11 "High energy battery state of charge on cell level";
CM_ SG_ 122 RatChaCellBattEgyHi_5_10 "High energy battery state of charge on cell level";
CM_ SG_ 122 RatChaCellBattEgyHi_5_9 "High energy battery state of charge on cell level";
CM_ SG_ 122 RatChaCellBattEgyHi_5_8 "High energy battery state of charge on cell level";
CM_ SG_ 122 RatChaCellBattEgyHi_5_7 "High energy battery state of charge on cell level";
CM_ SG_ 122 RatChaCellBattEgyHi_5_6 "High energy battery state of charge on cell level";
CM_ SG_ 122 RatChaCellBattEgyHi_5_5 "High energy battery state of charge on cell level";
CM_ SG_ 122 RatChaCellBattEgyHi_5_4 "High energy battery state of charge on cell level";
CM_ SG_ 122 RatChaCellBattEgyHi_5_3 "High energy battery state of charge on cell level";
CM_ SG_ 122 RatChaCellBattEgyHi_5_2 "High energy battery state of charge on cell level";
CM_ SG_ 122 RatChaCellBattEgyHi_5_1 "High energy battery state of charge on cell level";
CM_ SG_ 121 RatChaCellBattEgyHi_4_16 "High energy battery state of charge on cell level";
CM_ SG_ 121 RatChaCellBattEgyHi_4_15 "High energy battery state of charge on cell level";
CM_ SG_ 121 RatChaCellBattEgyHi_4_14 "High energy battery state of charge on cell level";
CM_ SG_ 121 RatChaCellBattEgyHi_4_13 "High energy battery state of charge on cell level";
CM_ SG_ 121 RatChaCellBattEgyHi_4_12 "High energy battery state of charge on cell level";
CM_ SG_ 121 RatChaCellBattEgyHi_4_11 "High energy battery state of charge on cell level";
CM_ SG_ 121 RatChaCellBattEgyHi_4_10 "High energy battery state of charge on cell level";
CM_ SG_ 121 RatChaCellBattEgyHi_4_9 "High energy battery state of charge on cell level";
CM_ SG_ 121 RatChaCellBattEgyHi_4_8 "High energy battery state of charge on cell level";
CM_ SG_ 121 RatChaCellBattEgyHi_4_7 "High energy battery state of charge on cell level";
CM_ SG_ 121 RatChaCellBattEgyHi_4_6 "High energy battery state of charge on cell level";
CM_ SG_ 121 RatChaCellBattEgyHi_4_5 "High energy battery state of charge on cell level";
CM_ SG_ 121 RatChaCellBattEgyHi_4_4 "High energy battery state of charge on cell level";
CM_ SG_ 121 RatChaCellBattEgyHi_4_3 "High energy battery state of charge on cell level";
CM_ SG_ 121 RatChaCellBattEgyHi_4_2 "High energy battery state of charge on cell level";
CM_ SG_ 121 RatChaCellBattEgyHi_4_1 "High energy battery state of charge on cell level";
CM_ SG_ 121 RatChaCellBattEgyHi_3_16 "High energy battery state of charge on cell level";
CM_ SG_ 121 RatChaCellBattEgyHi_3_15 "High energy battery state of charge on cell level";
CM_ SG_ 121 RatChaCellBattEgyHi_3_14 "High energy battery state of charge on cell level";
CM_ SG_ 121 RatChaCellBattEgyHi_3_13 "High energy battery state of charge on cell level";
CM_ SG_ 121 RatChaCellBattEgyHi_3_12 "High energy battery state of charge on cell level";
CM_ SG_ 121 RatChaCellBattEgyHi_3_11 "High energy battery state of charge on cell level";
CM_ SG_ 121 RatChaCellBattEgyHi_3_10 "High energy battery state of charge on cell level";
CM_ SG_ 121 RatChaCellBattEgyHi_3_9 "High energy battery state of charge on cell level";
CM_ SG_ 121 RatChaCellBattEgyHi_3_8 "High energy battery state of charge on cell level";
CM_ SG_ 121 RatChaCellBattEgyHi_3_7 "High energy battery state of charge on cell level";
CM_ SG_ 121 RatChaCellBattEgyHi_3_6 "High energy battery state of charge on cell level";
CM_ SG_ 121 RatChaCellBattEgyHi_3_5 "High energy battery state of charge on cell level";
CM_ SG_ 121 RatChaCellBattEgyHi_3_4 "High energy battery state of charge on cell level";
CM_ SG_ 121 RatChaCellBattEgyHi_3_3 "High energy battery state of charge on cell level";
CM_ SG_ 121 RatChaCellBattEgyHi_3_2 "High energy battery state of charge on cell level";
CM_ SG_ 121 RatChaCellBattEgyHi_3_1 "High energy battery state of charge on cell level";
CM_ SG_ 120 RatChaCellBattEgyHi_2_16 "High energy battery state of charge on cell level";
CM_ SG_ 120 RatChaCellBattEgyHi_2_15 "High energy battery state of charge on cell level";
CM_ SG_ 120 RatChaCellBattEgyHi_2_14 "High energy battery state of charge on cell level";
CM_ SG_ 120 RatChaCellBattEgyHi_2_13 "High energy battery state of charge on cell level";
CM_ SG_ 120 RatChaCellBattEgyHi_2_12 "High energy battery state of charge on cell level";
CM_ SG_ 120 RatChaCellBattEgyHi_2_11 "High energy battery state of charge on cell level";
CM_ SG_ 120 RatChaCellBattEgyHi_2_10 "High energy battery state of charge on cell level";
CM_ SG_ 120 RatChaCellBattEgyHi_2_9 "High energy battery state of charge on cell level";
CM_ SG_ 120 RatChaCellBattEgyHi_2_8 "High energy battery state of charge on cell level";
CM_ SG_ 120 RatChaCellBattEgyHi_2_7 "High energy battery state of charge on cell level";
CM_ SG_ 120 RatChaCellBattEgyHi_2_6 "High energy battery state of charge on cell level";
CM_ SG_ 120 RatChaCellBattEgyHi_2_5 "High energy battery state of charge on cell level";
CM_ SG_ 120 RatChaCellBattEgyHi_2_4 "High energy battery state of charge on cell level";
CM_ SG_ 120 RatChaCellBattEgyHi_2_3 "High energy battery state of charge on cell level";
CM_ SG_ 120 RatChaCellBattEgyHi_2_2 "High energy battery state of charge on cell level";
CM_ SG_ 120 RatChaCellBattEgyHi_2_1 "High energy battery state of charge on cell level";
CM_ SG_ 120 RatChaCellBattEgyHi_1_16 "High energy battery state of charge on cell level";
CM_ SG_ 120 RatChaCellBattEgyHi_1_15 "High energy battery state of charge on cell level";
CM_ SG_ 120 RatChaCellBattEgyHi_1_14 "High energy battery state of charge on cell level";
CM_ SG_ 120 RatChaCellBattEgyHi_1_13 "High energy battery state of charge on cell level";
CM_ SG_ 120 RatChaCellBattEgyHi_1_12 "High energy battery state of charge on cell level";
CM_ SG_ 120 RatChaCellBattEgyHi_1_11 "High energy battery state of charge on cell level";
CM_ SG_ 120 RatChaCellBattEgyHi_1_10 "High energy battery state of charge on cell level";
CM_ SG_ 120 RatChaCellBattEgyHi_1_9 "High energy battery state of charge on cell level";
CM_ SG_ 120 RatChaCellBattEgyHi_1_8 "High energy battery state of charge on cell level";
CM_ SG_ 120 RatChaCellBattEgyHi_1_7 "High energy battery state of charge on cell level";
CM_ SG_ 120 RatChaCellBattEgyHi_1_6 "High energy battery state of charge on cell level";
CM_ SG_ 120 RatChaCellBattEgyHi_1_5 "High energy battery state of charge on cell level";
CM_ SG_ 120 RatChaCellBattEgyHi_1_4 "High energy battery state of charge on cell level";
CM_ SG_ 120 RatChaCellBattEgyHi_1_3 "High energy battery state of charge on cell level";
CM_ SG_ 120 RatChaCellBattEgyHi_1_2 "High energy battery state of charge on cell level";
CM_ SG_ 120 RatChaCellBattEgyHi_1_1 "High energy battery state of charge on cell level";
CM_ SG_ 119 RatChaCellBattPwrHi_16_16 "High power battery state of charge on cell level";
CM_ SG_ 119 RatChaCellBattPwrHi_16_15 "High power battery state of charge on cell level";
CM_ SG_ 119 RatChaCellBattPwrHi_16_14 "High power battery state of charge on cell level";
CM_ SG_ 119 RatChaCellBattPwrHi_16_13 "High power battery state of charge on cell level";
CM_ SG_ 119 RatChaCellBattPwrHi_16_12 "High power battery state of charge on cell level";
CM_ SG_ 119 RatChaCellBattPwrHi_16_11 "High power battery state of charge on cell level";
CM_ SG_ 119 RatChaCellBattPwrHi_16_10 "High power battery state of charge on cell level";
CM_ SG_ 119 RatChaCellBattPwrHi_16_9 "High power battery state of charge on cell level";
CM_ SG_ 119 RatChaCellBattPwrHi_16_8 "High power battery state of charge on cell level";
CM_ SG_ 119 RatChaCellBattPwrHi_16_7 "High power battery state of charge on cell level";
CM_ SG_ 119 RatChaCellBattPwrHi_16_6 "High power battery state of charge on cell level";
CM_ SG_ 119 RatChaCellBattPwrHi_16_5 "High power battery state of charge on cell level";
CM_ SG_ 119 RatChaCellBattPwrHi_16_4 "High power battery state of charge on cell level";
CM_ SG_ 119 RatChaCellBattPwrHi_16_3 "High power battery state of charge on cell level";
CM_ SG_ 119 RatChaCellBattPwrHi_16_2 "High power battery state of charge on cell level";
CM_ SG_ 119 RatChaCellBattPwrHi_16_1 "High power battery state of charge on cell level";
CM_ SG_ 119 RatChaCellBattPwrHi_15_16 "High power battery state of charge on cell level";
CM_ SG_ 119 RatChaCellBattPwrHi_15_15 "High power battery state of charge on cell level";
CM_ SG_ 119 RatChaCellBattPwrHi_15_14 "High power battery state of charge on cell level";
CM_ SG_ 119 RatChaCellBattPwrHi_15_13 "High power battery state of charge on cell level";
CM_ SG_ 119 RatChaCellBattPwrHi_15_12 "High power battery state of charge on cell level";
CM_ SG_ 119 RatChaCellBattPwrHi_15_11 "High power battery state of charge on cell level";
CM_ SG_ 119 RatChaCellBattPwrHi_15_10 "High power battery state of charge on cell level";
CM_ SG_ 119 RatChaCellBattPwrHi_15_9 "High power battery state of charge on cell level";
CM_ SG_ 119 RatChaCellBattPwrHi_15_8 "High power battery state of charge on cell level";
CM_ SG_ 119 RatChaCellBattPwrHi_15_7 "High power battery state of charge on cell level";
CM_ SG_ 119 RatChaCellBattPwrHi_15_6 "High power battery state of charge on cell level";
CM_ SG_ 119 RatChaCellBattPwrHi_15_5 "High power battery state of charge on cell level";
CM_ SG_ 119 RatChaCellBattPwrHi_15_4 "High power battery state of charge on cell level";
CM_ SG_ 119 RatChaCellBattPwrHi_15_3 "High power battery state of charge on cell level";
CM_ SG_ 119 RatChaCellBattPwrHi_15_2 "High power battery state of charge on cell level";
CM_ SG_ 119 RatChaCellBattPwrHi_15_1 "High power battery state of charge on cell level";
CM_ SG_ 118 RatChaCellBattPwrHi_14_16 "High power battery state of charge on cell level";
CM_ SG_ 118 RatChaCellBattPwrHi_14_15 "High power battery state of charge on cell level";
CM_ SG_ 118 RatChaCellBattPwrHi_14_14 "High power battery state of charge on cell level";
CM_ SG_ 118 RatChaCellBattPwrHi_14_13 "High power battery state of charge on cell level";
CM_ SG_ 118 RatChaCellBattPwrHi_14_12 "High power battery state of charge on cell level";
CM_ SG_ 118 RatChaCellBattPwrHi_14_11 "High power battery state of charge on cell level";
CM_ SG_ 118 RatChaCellBattPwrHi_14_10 "High power battery state of charge on cell level";
CM_ SG_ 118 RatChaCellBattPwrHi_14_9 "High power battery state of charge on cell level";
CM_ SG_ 118 RatChaCellBattPwrHi_14_8 "High power battery state of charge on cell level";
CM_ SG_ 118 RatChaCellBattPwrHi_14_7 "High power battery state of charge on cell level";
CM_ SG_ 118 RatChaCellBattPwrHi_14_6 "High power battery state of charge on cell level";
CM_ SG_ 118 RatChaCellBattPwrHi_14_5 "High power battery state of charge on cell level";
CM_ SG_ 118 RatChaCellBattPwrHi_14_4 "High power battery state of charge on cell level";
CM_ SG_ 118 RatChaCellBattPwrHi_14_3 "High power battery state of charge on cell level";
CM_ SG_ 118 RatChaCellBattPwrHi_14_2 "High power battery state of charge on cell level";
CM_ SG_ 118 RatChaCellBattPwrHi_14_1 "High power battery state of charge on cell level";
CM_ SG_ 118 RatChaCellBattPwrHi_13_16 "High power battery state of charge on cell level";
CM_ SG_ 118 RatChaCellBattPwrHi_13_15 "High power battery state of charge on cell level";
CM_ SG_ 118 RatChaCellBattPwrHi_13_14 "High power battery state of charge on cell level";
CM_ SG_ 118 RatChaCellBattPwrHi_13_13 "High power battery state of charge on cell level";
CM_ SG_ 118 RatChaCellBattPwrHi_13_12 "High power battery state of charge on cell level";
CM_ SG_ 118 RatChaCellBattPwrHi_13_11 "High power battery state of charge on cell level";
CM_ SG_ 118 RatChaCellBattPwrHi_13_10 "High power battery state of charge on cell level";
CM_ SG_ 118 RatChaCellBattPwrHi_13_9 "High power battery state of charge on cell level";
CM_ SG_ 118 RatChaCellBattPwrHi_13_8 "High power battery state of charge on cell level";
CM_ SG_ 118 RatChaCellBattPwrHi_13_7 "High power battery state of charge on cell level";
CM_ SG_ 118 RatChaCellBattPwrHi_13_6 "High power battery state of charge on cell level";
CM_ SG_ 118 RatChaCellBattPwrHi_13_5 "High power battery state of charge on cell level";
CM_ SG_ 118 RatChaCellBattPwrHi_13_4 "High power battery state of charge on cell level";
CM_ SG_ 118 RatChaCellBattPwrHi_13_3 "High power battery state of charge on cell level";
CM_ SG_ 118 RatChaCellBattPwrHi_13_2 "High power battery state of charge on cell level";
CM_ SG_ 118 RatChaCellBattPwrHi_13_1 "High power battery state of charge on cell level";
CM_ SG_ 117 RatChaCellBattPwrHi_12_16 "High power battery state of charge on cell level";
CM_ SG_ 117 RatChaCellBattPwrHi_12_15 "High power battery state of charge on cell level";
CM_ SG_ 117 RatChaCellBattPwrHi_12_14 "High power battery state of charge on cell level";
CM_ SG_ 117 RatChaCellBattPwrHi_12_13 "High power battery state of charge on cell level";
CM_ SG_ 117 RatChaCellBattPwrHi_12_12 "High power battery state of charge on cell level";
CM_ SG_ 117 RatChaCellBattPwrHi_12_11 "High power battery state of charge on cell level";
CM_ SG_ 117 RatChaCellBattPwrHi_12_10 "High power battery state of charge on cell level";
CM_ SG_ 117 RatChaCellBattPwrHi_12_9 "High power battery state of charge on cell level";
CM_ SG_ 117 RatChaCellBattPwrHi_12_8 "High power battery state of charge on cell level";
CM_ SG_ 117 RatChaCellBattPwrHi_12_7 "High power battery state of charge on cell level";
CM_ SG_ 117 RatChaCellBattPwrHi_12_6 "High power battery state of charge on cell level";
CM_ SG_ 117 RatChaCellBattPwrHi_12_5 "High power battery state of charge on cell level";
CM_ SG_ 117 RatChaCellBattPwrHi_12_4 "High power battery state of charge on cell level";
CM_ SG_ 117 RatChaCellBattPwrHi_12_3 "High power battery state of charge on cell level";
CM_ SG_ 117 RatChaCellBattPwrHi_12_2 "High power battery state of charge on cell level";
CM_ SG_ 117 RatChaCellBattPwrHi_12_1 "High power battery state of charge on cell level";
CM_ SG_ 117 RatChaCellBattPwrHi_11_16 "High power battery state of charge on cell level";
CM_ SG_ 117 RatChaCellBattPwrHi_11_15 "High power battery state of charge on cell level";
CM_ SG_ 117 RatChaCellBattPwrHi_11_14 "High power battery state of charge on cell level";
CM_ SG_ 117 RatChaCellBattPwrHi_11_13 "High power battery state of charge on cell level";
CM_ SG_ 117 RatChaCellBattPwrHi_11_12 "High power battery state of charge on cell level";
CM_ SG_ 117 RatChaCellBattPwrHi_11_11 "High power battery state of charge on cell level";
CM_ SG_ 117 RatChaCellBattPwrHi_11_10 "High power battery state of charge on cell level";
CM_ SG_ 117 RatChaCellBattPwrHi_11_9 "High power battery state of charge on cell level";
CM_ SG_ 117 RatChaCellBattPwrHi_11_8 "High power battery state of charge on cell level";
CM_ SG_ 117 RatChaCellBattPwrHi_11_7 "High power battery state of charge on cell level";
CM_ SG_ 117 RatChaCellBattPwrHi_11_6 "High power battery state of charge on cell level";
CM_ SG_ 117 RatChaCellBattPwrHi_11_5 "High power battery state of charge on cell level";
CM_ SG_ 117 RatChaCellBattPwrHi_11_4 "High power battery state of charge on cell level";
CM_ SG_ 117 RatChaCellBattPwrHi_11_3 "High power battery state of charge on cell level";
CM_ SG_ 117 RatChaCellBattPwrHi_11_2 "High power battery state of charge on cell level";
CM_ SG_ 117 RatChaCellBattPwrHi_11_1 "High power battery state of charge on cell level";
CM_ SG_ 116 RatChaCellBattPwrHi_10_16 "High power battery state of charge on cell level";
CM_ SG_ 116 RatChaCellBattPwrHi_10_15 "High power battery state of charge on cell level";
CM_ SG_ 116 RatChaCellBattPwrHi_10_14 "High power battery state of charge on cell level";
CM_ SG_ 116 RatChaCellBattPwrHi_10_13 "High power battery state of charge on cell level";
CM_ SG_ 116 RatChaCellBattPwrHi_10_12 "High power battery state of charge on cell level";
CM_ SG_ 116 RatChaCellBattPwrHi_10_11 "High power battery state of charge on cell level";
CM_ SG_ 116 RatChaCellBattPwrHi_10_10 "High power battery state of charge on cell level";
CM_ SG_ 116 RatChaCellBattPwrHi_10_9 "High power battery state of charge on cell level";
CM_ SG_ 116 RatChaCellBattPwrHi_10_8 "High power battery state of charge on cell level";
CM_ SG_ 116 RatChaCellBattPwrHi_10_7 "High power battery state of charge on cell level";
CM_ SG_ 116 RatChaCellBattPwrHi_10_6 "High power battery state of charge on cell level";
CM_ SG_ 116 RatChaCellBattPwrHi_10_5 "High power battery state of charge on cell level";
CM_ SG_ 116 RatChaCellBattPwrHi_10_4 "High power battery state of charge on cell level";
CM_ SG_ 116 RatChaCellBattPwrHi_10_3 "High power battery state of charge on cell level";
CM_ SG_ 116 RatChaCellBattPwrHi_10_2 "High power battery state of charge on cell level";
CM_ SG_ 116 RatChaCellBattPwrHi_10_1 "High power battery state of charge on cell level";
CM_ SG_ 116 RatChaCellBattPwrHi_9_16 "High power battery state of charge on cell level";
CM_ SG_ 116 RatChaCellBattPwrHi_9_15 "High power battery state of charge on cell level";
CM_ SG_ 116 RatChaCellBattPwrHi_9_14 "High power battery state of charge on cell level";
CM_ SG_ 116 RatChaCellBattPwrHi_9_13 "High power battery state of charge on cell level";
CM_ SG_ 116 RatChaCellBattPwrHi_9_12 "High power battery state of charge on cell level";
CM_ SG_ 116 RatChaCellBattPwrHi_9_11 "High power battery state of charge on cell level";
CM_ SG_ 116 RatChaCellBattPwrHi_9_10 "High power battery state of charge on cell level";
CM_ SG_ 116 RatChaCellBattPwrHi_9_9 "High power battery state of charge on cell level";
CM_ SG_ 116 RatChaCellBattPwrHi_9_8 "High power battery state of charge on cell level";
CM_ SG_ 116 RatChaCellBattPwrHi_9_7 "High power battery state of charge on cell level";
CM_ SG_ 116 RatChaCellBattPwrHi_9_6 "High power battery state of charge on cell level";
CM_ SG_ 116 RatChaCellBattPwrHi_9_5 "High power battery state of charge on cell level";
CM_ SG_ 116 RatChaCellBattPwrHi_9_4 "High power battery state of charge on cell level";
CM_ SG_ 116 RatChaCellBattPwrHi_9_3 "High power battery state of charge on cell level";
CM_ SG_ 116 RatChaCellBattPwrHi_9_2 "High power battery state of charge on cell level";
CM_ SG_ 116 RatChaCellBattPwrHi_9_1 "High power battery state of charge on cell level";
CM_ SG_ 115 RatChaCellBattPwrHi_8_16 "High power battery state of charge on cell level";
CM_ SG_ 115 RatChaCellBattPwrHi_8_15 "High power battery state of charge on cell level";
CM_ SG_ 115 RatChaCellBattPwrHi_8_14 "High power battery state of charge on cell level";
CM_ SG_ 115 RatChaCellBattPwrHi_8_13 "High power battery state of charge on cell level";
CM_ SG_ 115 RatChaCellBattPwrHi_8_12 "High power battery state of charge on cell level";
CM_ SG_ 115 RatChaCellBattPwrHi_8_11 "High power battery state of charge on cell level";
CM_ SG_ 115 RatChaCellBattPwrHi_8_10 "High power battery state of charge on cell level";
CM_ SG_ 115 RatChaCellBattPwrHi_8_9 "High power battery state of charge on cell level";
CM_ SG_ 115 RatChaCellBattPwrHi_8_8 "High power battery state of charge on cell level";
CM_ SG_ 115 RatChaCellBattPwrHi_8_7 "High power battery state of charge on cell level";
CM_ SG_ 115 RatChaCellBattPwrHi_8_6 "High power battery state of charge on cell level";
CM_ SG_ 115 RatChaCellBattPwrHi_8_5 "High power battery state of charge on cell level";
CM_ SG_ 115 RatChaCellBattPwrHi_8_4 "High power battery state of charge on cell level";
CM_ SG_ 115 RatChaCellBattPwrHi_8_3 "High power battery state of charge on cell level";
CM_ SG_ 115 RatChaCellBattPwrHi_8_2 "High power battery state of charge on cell level";
CM_ SG_ 115 RatChaCellBattPwrHi_8_1 "High power battery state of charge on cell level";
CM_ SG_ 115 RatChaCellBattPwrHi_7_16 "High power battery state of charge on cell level";
CM_ SG_ 115 RatChaCellBattPwrHi_7_15 "High power battery state of charge on cell level";
CM_ SG_ 115 RatChaCellBattPwrHi_7_14 "High power battery state of charge on cell level";
CM_ SG_ 115 RatChaCellBattPwrHi_7_13 "High power battery state of charge on cell level";
CM_ SG_ 115 RatChaCellBattPwrHi_7_12 "High power battery state of charge on cell level";
CM_ SG_ 115 RatChaCellBattPwrHi_7_11 "High power battery state of charge on cell level";
CM_ SG_ 115 RatChaCellBattPwrHi_7_10 "High power battery state of charge on cell level";
CM_ SG_ 115 RatChaCellBattPwrHi_7_9 "High power battery state of charge on cell level";
CM_ SG_ 115 RatChaCellBattPwrHi_7_8 "High power battery state of charge on cell level";
CM_ SG_ 115 RatChaCellBattPwrHi_7_7 "High power battery state of charge on cell level";
CM_ SG_ 115 RatChaCellBattPwrHi_7_6 "High power battery state of charge on cell level";
CM_ SG_ 115 RatChaCellBattPwrHi_7_5 "High power battery state of charge on cell level";
CM_ SG_ 115 RatChaCellBattPwrHi_7_4 "High power battery state of charge on cell level";
CM_ SG_ 115 RatChaCellBattPwrHi_7_3 "High power battery state of charge on cell level";
CM_ SG_ 115 RatChaCellBattPwrHi_7_2 "High power battery state of charge on cell level";
CM_ SG_ 115 RatChaCellBattPwrHi_7_1 "High power battery state of charge on cell level";
CM_ SG_ 114 RatChaCellBattPwrHi_6_16 "High power battery state of charge on cell level";
CM_ SG_ 114 RatChaCellBattPwrHi_6_15 "High power battery state of charge on cell level";
CM_ SG_ 114 RatChaCellBattPwrHi_6_14 "High power battery state of charge on cell level";
CM_ SG_ 114 RatChaCellBattPwrHi_6_13 "High power battery state of charge on cell level";
CM_ SG_ 114 RatChaCellBattPwrHi_6_12 "High power battery state of charge on cell level";
CM_ SG_ 114 RatChaCellBattPwrHi_6_11 "High power battery state of charge on cell level";
CM_ SG_ 114 RatChaCellBattPwrHi_6_10 "High power battery state of charge on cell level";
CM_ SG_ 114 RatChaCellBattPwrHi_6_9 "High power battery state of charge on cell level";
CM_ SG_ 114 RatChaCellBattPwrHi_6_8 "High power battery state of charge on cell level";
CM_ SG_ 114 RatChaCellBattPwrHi_6_7 "High power battery state of charge on cell level";
CM_ SG_ 114 RatChaCellBattPwrHi_6_6 "High power battery state of charge on cell level";
CM_ SG_ 114 RatChaCellBattPwrHi_6_5 "High power battery state of charge on cell level";
CM_ SG_ 114 RatChaCellBattPwrHi_6_4 "High power battery state of charge on cell level";
CM_ SG_ 114 RatChaCellBattPwrHi_6_3 "High power battery state of charge on cell level";
CM_ SG_ 114 RatChaCellBattPwrHi_6_2 "High power battery state of charge on cell level";
CM_ SG_ 114 RatChaCellBattPwrHi_6_1 "High power battery state of charge on cell level";
CM_ SG_ 114 RatChaCellBattPwrHi_5_16 "High power battery state of charge on cell level";
CM_ SG_ 114 RatChaCellBattPwrHi_5_15 "High power battery state of charge on cell level";
CM_ SG_ 114 RatChaCellBattPwrHi_5_14 "High power battery state of charge on cell level";
CM_ SG_ 114 RatChaCellBattPwrHi_5_13 "High power battery state of charge on cell level";
CM_ SG_ 114 RatChaCellBattPwrHi_5_12 "High power battery state of charge on cell level";
CM_ SG_ 114 RatChaCellBattPwrHi_5_11 "High power battery state of charge on cell level";
CM_ SG_ 114 RatChaCellBattPwrHi_5_10 "High power battery state of charge on cell level";
CM_ SG_ 114 RatChaCellBattPwrHi_5_9 "High power battery state of charge on cell level";
CM_ SG_ 114 RatChaCellBattPwrHi_5_8 "High power battery state of charge on cell level";
CM_ SG_ 114 RatChaCellBattPwrHi_5_7 "High power battery state of charge on cell level";
CM_ SG_ 114 RatChaCellBattPwrHi_5_6 "High power battery state of charge on cell level";
CM_ SG_ 114 RatChaCellBattPwrHi_5_5 "High power battery state of charge on cell level";
CM_ SG_ 114 RatChaCellBattPwrHi_5_4 "High power battery state of charge on cell level";
CM_ SG_ 114 RatChaCellBattPwrHi_5_3 "High power battery state of charge on cell level";
CM_ SG_ 114 RatChaCellBattPwrHi_5_2 "High power battery state of charge on cell level";
CM_ SG_ 114 RatChaCellBattPwrHi_5_1 "High power battery state of charge on cell level";
CM_ SG_ 113 RatChaCellBattPwrHi_4_16 "High power battery state of charge on cell level";
CM_ SG_ 113 RatChaCellBattPwrHi_4_15 "High power battery state of charge on cell level";
CM_ SG_ 113 RatChaCellBattPwrHi_4_14 "High power battery state of charge on cell level";
CM_ SG_ 113 RatChaCellBattPwrHi_4_13 "High power battery state of charge on cell level";
CM_ SG_ 113 RatChaCellBattPwrHi_4_12 "High power battery state of charge on cell level";
CM_ SG_ 113 RatChaCellBattPwrHi_4_11 "High power battery state of charge on cell level";
CM_ SG_ 113 RatChaCellBattPwrHi_4_10 "High power battery state of charge on cell level";
CM_ SG_ 113 RatChaCellBattPwrHi_4_9 "High power battery state of charge on cell level";
CM_ SG_ 113 RatChaCellBattPwrHi_4_8 "High power battery state of charge on cell level";
CM_ SG_ 113 RatChaCellBattPwrHi_4_7 "High power battery state of charge on cell level";
CM_ SG_ 113 RatChaCellBattPwrHi_4_6 "High power battery state of charge on cell level";
CM_ SG_ 113 RatChaCellBattPwrHi_4_5 "High power battery state of charge on cell level";
CM_ SG_ 113 RatChaCellBattPwrHi_4_4 "High power battery state of charge on cell level";
CM_ SG_ 113 RatChaCellBattPwrHi_4_3 "High power battery state of charge on cell level";
CM_ SG_ 113 RatChaCellBattPwrHi_4_2 "High power battery state of charge on cell level";
CM_ SG_ 113 RatChaCellBattPwrHi_4_1 "High power battery state of charge on cell level";
CM_ SG_ 113 RatChaCellBattPwrHi_3_16 "High power battery state of charge on cell level";
CM_ SG_ 113 RatChaCellBattPwrHi_3_15 "High power battery state of charge on cell level";
CM_ SG_ 113 RatChaCellBattPwrHi_3_14 "High power battery state of charge on cell level";
CM_ SG_ 113 RatChaCellBattPwrHi_3_13 "High power battery state of charge on cell level";
CM_ SG_ 113 RatChaCellBattPwrHi_3_12 "High power battery state of charge on cell level";
CM_ SG_ 113 RatChaCellBattPwrHi_3_11 "High power battery state of charge on cell level";
CM_ SG_ 113 RatChaCellBattPwrHi_3_10 "High power battery state of charge on cell level";
CM_ SG_ 113 RatChaCellBattPwrHi_3_9 "High power battery state of charge on cell level";
CM_ SG_ 113 RatChaCellBattPwrHi_3_8 "High power battery state of charge on cell level";
CM_ SG_ 113 RatChaCellBattPwrHi_3_7 "High power battery state of charge on cell level";
CM_ SG_ 113 RatChaCellBattPwrHi_3_6 "High power battery state of charge on cell level";
CM_ SG_ 113 RatChaCellBattPwrHi_3_5 "High power battery state of charge on cell level";
CM_ SG_ 113 RatChaCellBattPwrHi_3_4 "High power battery state of charge on cell level";
CM_ SG_ 113 RatChaCellBattPwrHi_3_3 "High power battery state of charge on cell level";
CM_ SG_ 113 RatChaCellBattPwrHi_3_2 "High power battery state of charge on cell level";
CM_ SG_ 113 RatChaCellBattPwrHi_3_1 "High power battery state of charge on cell level";
BA_DEF_ BO_  "GenMsgSendType" ENUM  "Cyclic";
BA_DEF_ SG_  "GenSigSendType" ENUM  "Cyclic";
BA_DEF_ BO_  "GenMsgCycleTime" INT 0 65535;
BA_DEF_ BO_  "CANFD_BRS" ENUM  "0","1";
BA_DEF_  "DBName" STRING ;
BA_DEF_  "BusType" STRING ;
BA_DEF_ BO_  "VFrameFormat" ENUM  "StandardCAN","ExtendedCAN","reserved","reserved","reserved","reserved","reserved","reserved","reserved","reserved","reserved","reserved","reserved","reserved","StandardCAN_FD","ExtendedCAN_FD";
BA_DEF_DEF_  "GenMsgSendType" "Cyclic";
BA_DEF_DEF_  "GenSigSendType" "Cyclic";
BA_DEF_DEF_  "GenMsgCycleTime" 1000;
BA_DEF_DEF_  "CANFD_BRS" "1";
BA_DEF_DEF_  "DBName" "";
BA_DEF_DEF_  "BusType" "";
BA_DEF_DEF_  "VFrameFormat" "StandardCAN";
BA_ "BusType" "CAN FD";
BA_ "DBName" "IOT_CAN";
BA_ "VFrameFormat" BO_ 130 14;
BA_ "VFrameFormat" BO_ 111 14;
BA_ "VFrameFormat" BO_ 110 14;
BA_ "VFrameFormat" BO_ 109 14;
BA_ "VFrameFormat" BO_ 108 14;
BA_ "VFrameFormat" BO_ 95 14;
BA_ "VFrameFormat" BO_ 94 14;
BA_ "VFrameFormat" BO_ 93 14;
BA_ "VFrameFormat" BO_ 92 14;
BA_ "VFrameFormat" BO_ 127 14;
BA_ "VFrameFormat" BO_ 126 14;
BA_ "VFrameFormat" BO_ 125 14;
BA_ "VFrameFormat" BO_ 124 14;
BA_ "VFrameFormat" BO_ 123 14;
BA_ "VFrameFormat" BO_ 122 14;
BA_ "VFrameFormat" BO_ 121 14;
BA_ "VFrameFormat" BO_ 120 14;
BA_ "VFrameFormat" BO_ 119 14;
BA_ "VFrameFormat" BO_ 118 14;
BA_ "VFrameFormat" BO_ 117 14;
BA_ "VFrameFormat" BO_ 116 14;
BA_ "VFrameFormat" BO_ 115 14;
BA_ "VFrameFormat" BO_ 114 14;
BA_ "VFrameFormat" BO_ 113 14;
